VERSION "created by canmatrix"

NS_ :

BS_:

BU_: ETAS SRRL SRRR FRR IBC EPS

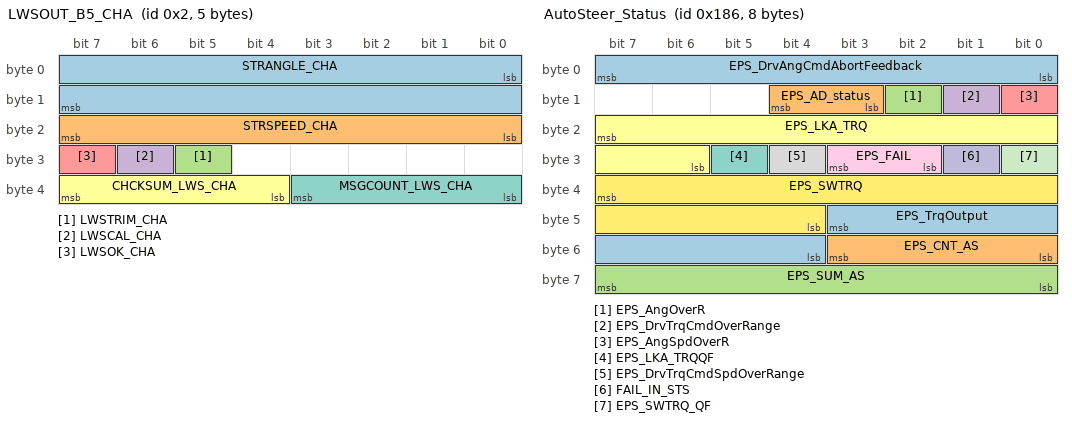
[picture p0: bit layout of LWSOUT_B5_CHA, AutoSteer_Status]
BO_ 2 LWSOUT_B5_CHA: 5 EPS
 SG_ STRANGLE_CHA : 0|16@1- (0.1,0) [-780|780] "deg"  ETAS,SRRL,SRRR,FRR
 SG_ STRSPEED_CHA : 16|8@1+ (4,0) [0|1016] "deg/s"  ETAS,SRRL,SRRR,FRR
 SG_ LWSTRIM_CHA : 29|1@1+ (1,0) [0|1] ""  ETAS,SRRL,SRRR,FRR
 SG_ LWSCAL_CHA : 30|1@1+ (1,0) [0|1] ""  ETAS,SRRL,SRRR,FRR
 SG_ LWSOK_CHA : 31|1@1+ (1,0) [0|1] ""  ETAS,SRRL,SRRR,FRR
 SG_ CHCKSUM_LWS_CHA : 36|4@1+ (1,0) [0|15] ""  ETAS,SRRL,SRRR,FRR
 SG_ MSGCOUNT_LWS_CHA : 32|4@1+ (1,0) [0|15] ""  ETAS,SRRL,SRRR,FRR

BO_ 390 AutoSteer_Status: 8 EPS
 SG_ EPS_DrvAngCmdAbortFeedback : 7|8@0+ (1,0) [0|128] ""  ETAS
 SG_ EPS_AD_status : 12|2@0+ (1,0) [0|3] ""  ETAS
 SG_ EPS_AngOverR : 10|1@0+ (1,0) [0|1] ""  ETAS
 SG_ EPS_DrvTrqCmdOverRange : 9|1@0+ (1,0) [0|1] ""  ETAS
 SG_ EPS_AngSpdOverR : 8|1@0+ (1,0) [0|1] ""  ETAS
 SG_ EPS_LKA_TRQ : 23|10@0- (0.01,0) [-5|5] "Nm"  ETAS
 SG_ EPS_LKA_TRQQF : 29|1@0+ (1,0) [0|1] ""  ETAS
 SG_ EPS_DrvTrqCmdSpdOverRange : 28|1@0+ (1,0) [0|1] ""  ETAS
 SG_ EPS_FAIL : 27|2@0+ (1,0) [0|3] ""  ETAS
 SG_ FAIL_IN_STS : 25|1@0+ (1,0) [0|1] ""  ETAS
 SG_ EPS_SWTRQ_QF : 24|1@0+ (1,0) [0|1] ""  ETAS
 SG_ EPS_SWTRQ : 39|12@0- (0.01,0) [-12|12] "Nm"  ETAS
 SG_ EPS_TrqOutput : 43|8@0- (0.1,0) [-12|12] "Nm"  ETAS
 SG_ EPS_CNT_AS : 51|4@0+ (1,0) [0|15] ""  ETAS
 SG_ EPS_SUM_AS : 63|8@0+ (1,0) [0|255] ""  ETAS

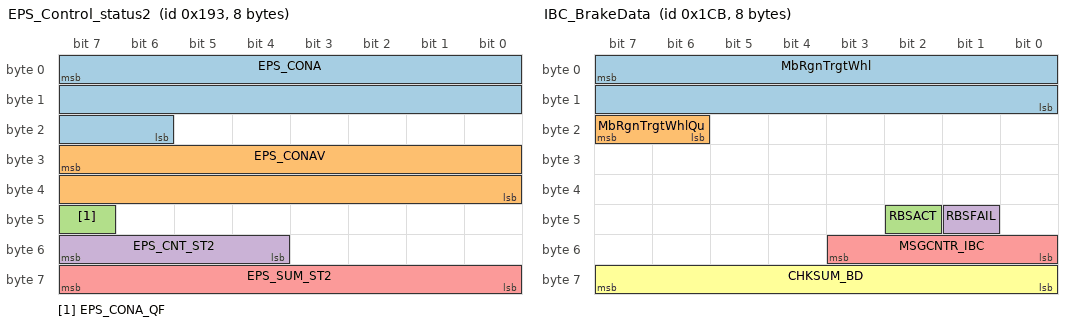
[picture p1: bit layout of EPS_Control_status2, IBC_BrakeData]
BO_ 403 EPS_Control_status2: 8 EPS
 SG_ EPS_CONA : 7|18@0- (0.01,0) [-780|780] "deg"  ETAS
 SG_ EPS_CONAV : 31|16@0+ (0.1,-1000) [-1000|1000] "deg/s"  ETAS
 SG_ EPS_CONA_QF : 47|1@0+ (1,0) [0|1] ""  ETAS
 SG_ EPS_CNT_ST2 : 55|4@0+ (1,0) [0|15] ""  ETAS
 SG_ EPS_SUM_ST2 : 63|8@0+ (1,0) [0|255] ""  ETAS

BO_ 682 BrakeSystemtoADAS_MSG1_CHA: 8 IBC
 SG_ ADAS_PTC_STATUS_CHA : 11|2@0+ (1,0) [0|3] ""  ETAS
 SG_ SIGNAL_SOURCING_CHA : 9|2@0+ (1,0) [0|3] ""  ETAS
 SG_ AEB_ENBL_CHA : 23|1@0+ (1,0) [0|1] ""  ETAS
 SG_ AEB_STATUS_CHA : 22|1@0+ (1,0) [0|1] ""  ETAS,SRRL,SRRR,FRR
 SG_ AEB_ALIVE_CHA : 21|1@0+ (1,0) [0|1] ""  ETAS
 SG_ PREFILL_ENBL_CHA : 20|1@0+ (1,0) [0|1] ""  ETAS
 SG_ PREFILL_STATUS_CHA : 19|1@0+ (1,0) [0|1] ""  ETAS
 SG_ PREFILL_ALIVE_CHA : 18|1@0+ (1,0) [0|1] ""  ETAS
 SG_ ABA_ENBL_CHA : 17|1@0+ (1,0) [0|1] ""  ETAS
 SG_ ABA_STATUS_CHA : 16|1@0+ (1,0) [0|1] ""  ETAS
 SG_ ABA_ALIVE_CHA : 31|1@0+ (1,0) [0|1] ""  ETAS
 SG_ AWB_ENBL_CHA : 30|1@0+ (1,0) [0|1] ""  ETAS
 SG_ AWB_STATUS_CHA : 29|1@0+ (1,0) [0|1] ""  ETAS
 SG_ AWB_ALIVE_CHA : 28|1@0+ (1,0) [0|1] ""  ETAS
 SG_ ACC_CDD_ENBL_CHA : 27|1@0+ (1,0) [0|1] ""  ETAS
 SG_ ACC_CDD_STATUS_CHA : 26|1@0+ (1,0) [0|1] ""  ETAS
 SG_ ACC_CDD_ALIVE_CHA : 25|1@0+ (1,0) [0|1] ""  ETAS
 SG_ ACC_CDD_TEMP_CHA : 36|1@0+ (1,0) [0|1] ""  ETAS
 SG_ WCBF_EXIST_CHA : 54|1@0+ (1,0) [0|1] ""  ETAS
 SG_ VEH_STD_STILL_CHA : 53|2@0+ (1,0) [0|3] ""  ETAS,SRRL,SRRR,FRR
 SG_ MSG_CNT_BAM_CHA : 51|4@0+ (1,0) [0|15] ""  ETAS,SRRL,SRRR,FRR
 SG_ CHKSUM_BAM_CHA : 63|8@0+ (1,0) [0|255] ""  ETAS,SRRL,SRRR,FRR

BO_ 459 IBC_BrakeData: 8 IBC
 SG_ MbRgnTrgtWhl : 7|16@0+ (1,0) [0|32768] "Nm"  ETAS
 SG_ MbRgnTrgtWhlQu : 23|2@0+ (1,0) [0|2] ""  ETAS
 SG_ RBSACT : 42|1@0+ (1,0) [0|1] ""  ETAS
 SG_ RBSFAIL : 41|1@0+ (1,0) [0|1] ""  ETAS
 SG_ MSGCNTR_IBC : 51|4@0+ (1,0) [0|15] ""  ETAS
 SG_ CHKSUM_BD : 63|8@0+ (1,0) [0|255] ""  ETAS

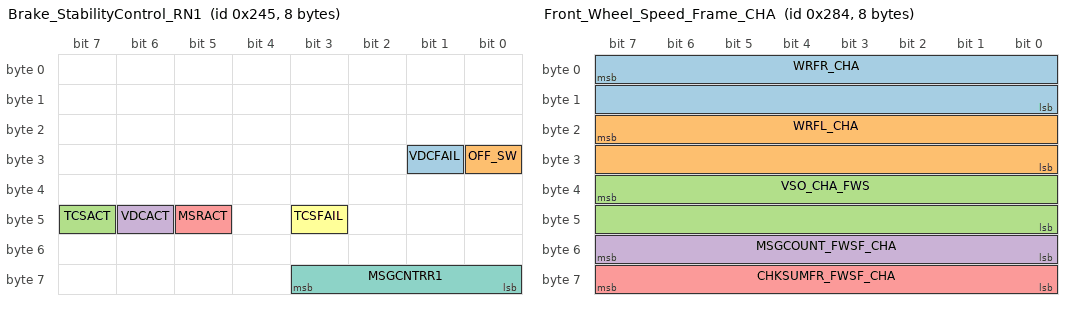
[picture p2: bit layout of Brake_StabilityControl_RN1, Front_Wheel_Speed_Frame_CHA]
BO_ 581 Brake_StabilityControl_RN1: 8 IBC
 SG_ VDCFAIL : 25|1@0+ (1,0) [0|1] ""  ETAS
 SG_ OFF_SW : 24|1@0+ (1,0) [0|1] ""  ETAS
 SG_ TCSACT : 47|1@0+ (1,0) [0|1] ""  ETAS
 SG_ VDCACT : 46|1@0+ (1,0) [0|1] ""  ETAS
 SG_ MSRACT : 45|1@0+ (1,0) [0|1] ""  ETAS
 SG_ TCSFAIL : 43|1@0+ (1,0) [0|1] ""  ETAS
 SG_ MSGCNTRR1 : 59|4@0+ (1,0) [0|15] ""  ETAS

BO_ 644 Front_Wheel_Speed_Frame_CHA: 8 IBC
 SG_ WRFR_CHA : 7|16@0+ (0.0416666666666667,0) [0|2730.58333333333] "rpm"  ETAS,SRRL,SRRR,FRR
 SG_ WRFL_CHA : 23|16@0+ (0.0416666666666667,0) [0|2730.58333333333] "rpm"  ETAS,SRRL,SRRR,FRR
 SG_ VSO_CHA_FWS : 39|16@0+ (0.01,0) [0|655.34] "km/h"  ETAS,SRRL,SRRR,FRR
 SG_ MSGCOUNT_FWSF_CHA : 55|8@0+ (1,0) [0|255] ""  ETAS,SRRL,SRRR,FRR
 SG_ CHKSUMFR_FWSF_CHA : 63|8@0+ (1,0) [0|255] ""  ETAS,SRRL,SRRR,FRR

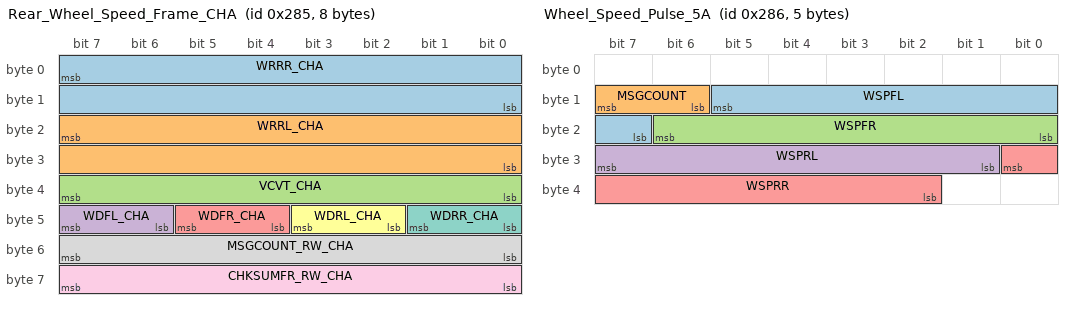
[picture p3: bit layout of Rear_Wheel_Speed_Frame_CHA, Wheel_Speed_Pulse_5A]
BO_ 645 Rear_Wheel_Speed_Frame_CHA: 8 IBC
 SG_ WRRR_CHA : 7|16@0+ (0.0416666666666667,0) [0|2730.58333333333] "rpm"  ETAS,SRRL,SRRR,FRR
 SG_ WRRL_CHA : 23|16@0+ (0.0416666666666667,0) [0|2730.58333333333] "rpm"  ETAS,SRRL,SRRR,FRR
 SG_ VCVT_CHA : 39|8@0+ (1,0) [0|255] "km/h"  ETAS,SRRL,SRRR,FRR
 SG_ WDFL_CHA : 47|2@0+ (1,0) [0|3] ""  ETAS,SRRL,SRRR,FRR
 SG_ WDFR_CHA : 45|2@0+ (1,0) [0|3] ""  ETAS,SRRL,SRRR,FRR
 SG_ WDRL_CHA : 43|2@0+ (1,0) [0|3] ""  ETAS,SRRL,SRRR,FRR
 SG_ WDRR_CHA : 41|2@0+ (1,0) [0|3] ""  ETAS,SRRL,SRRR,FRR
 SG_ MSGCOUNT_RW_CHA : 55|8@0+ (1,0) [0|255] ""  ETAS,SRRL,SRRR,FRR
 SG_ CHKSUMFR_RW_CHA : 63|8@0+ (1,0) [0|255] ""  ETAS,SRRL,SRRR,FRR

BO_ 646 Wheel_Speed_Pulse_5A: 5 IBC
 SG_ WSPFL : 13|7@0+ (1,0) [1|96] "top"  ETAS
 SG_ MSGCOUNT : 15|2@0+ (1,0) [0|3] ""  ETAS
 SG_ WSPFR : 22|7@0+ (1,0) [1|96] "top"  ETAS
 SG_ WSPRL : 31|7@0+ (1,0) [1|96] "top"  ETAS
 SG_ WSPRR : 24|7@0+ (1,0) [1|96] "top"  ETAS

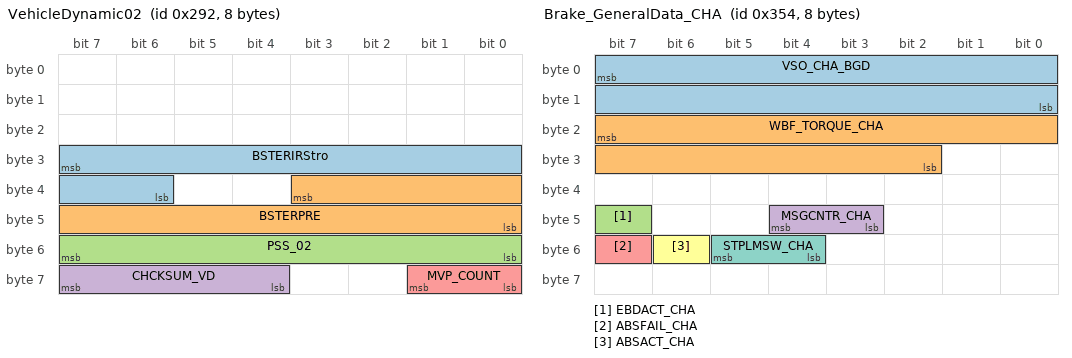
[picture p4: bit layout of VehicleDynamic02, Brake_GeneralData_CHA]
BO_ 658 VehicleDynamic02: 8 IBC
 SG_ BSTERIRStro : 31|10@0+ (0.05,-5) [-5|46.1] "mm"  ETAS
 SG_ BSTERPRE : 35|12@0+ (0.1,-5) [-5|302.1] "bar"  ETAS
 SG_ PSS_02 : 55|8@0+ (1,0) [0|254] "bar"  ETAS
 SG_ CHCKSUM_VD : 63|4@0+ (1,0) [0|15] ""  ETAS
 SG_ MVP_COUNT : 57|2@0+ (1,0) [0|3] ""  ETAS

BO_ 852 Brake_GeneralData_CHA: 8 IBC
 SG_ VSO_CHA_BGD : 7|16@0+ (0.01,0) [0|655.34] "km/h"  ETAS
 SG_ WBF_TORQUE_CHA : 23|14@0+ (2,0) [0|32764] "NM"  ETAS
 SG_ EBDACT_CHA : 47|1@0+ (1,0) [0|1] ""  ETAS,SRRL,SRRR,FRR
 SG_ MSGCNTR_CHA : 44|2@0+ (1,0) [0|3] ""  ETAS,SRRL,SRRR,FRR
 SG_ ABSFAIL_CHA : 55|1@0+ (1,0) [0|1] ""  ETAS,SRRL,SRRR,FRR
 SG_ ABSACT_CHA : 54|1@0+ (1,0) [0|1] ""  ETAS,SRRL,SRRR,FRR
 SG_ STPLMSW_CHA : 53|2@0+ (1,0) [0|3] ""  ETAS,SRRL,SRRR,FRR

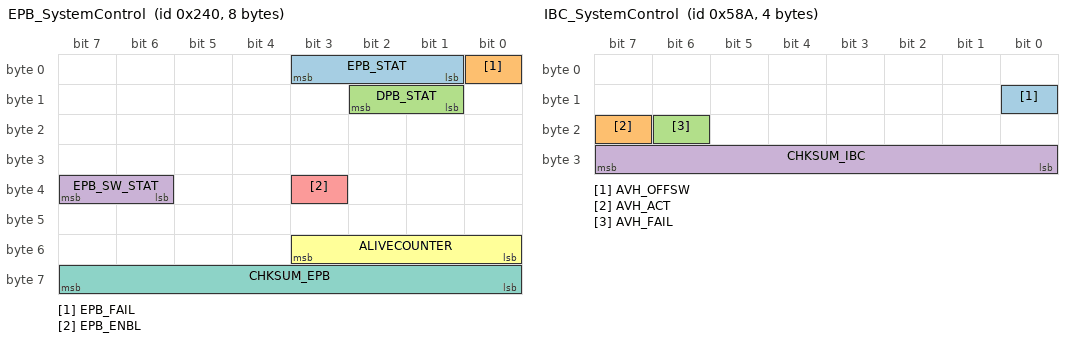
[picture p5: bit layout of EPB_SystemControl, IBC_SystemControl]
BO_ 576 EPB_SystemControl: 8 IBC
 SG_ EPB_STAT : 3|3@0+ (1,0) [0|7] ""  ETAS
 SG_ EPB_FAIL : 0|1@0+ (1,0) [0|1] ""  ETAS
 SG_ DPB_STAT : 10|2@0+ (1,0) [0|3] ""  ETAS
 SG_ EPB_SW_STAT : 39|2@0+ (1,0) [0|3] ""  ETAS
 SG_ EPB_ENBL : 35|1@0+ (1,0) [0|1] ""  ETAS
 SG_ ALIVECOUNTER : 51|4@0+ (1,0) [0|15] ""  ETAS
 SG_ CHKSUM_EPB : 63|8@0+ (1,0) [0|255] ""  ETAS

BO_ 1418 IBC_SystemControl: 4 IBC
 SG_ AVH_OFFSW : 8|1@0+ (1,0) [0|1] ""  ETAS
 SG_ AVH_ACT : 23|1@0+ (1,0) [0|1] ""  ETAS
 SG_ AVH_FAIL : 22|1@0+ (1,0) [0|1] ""  ETAS
 SG_ CHKSUM_IBC : 31|8@0+ (1,0) [0|255] ""  ETAS

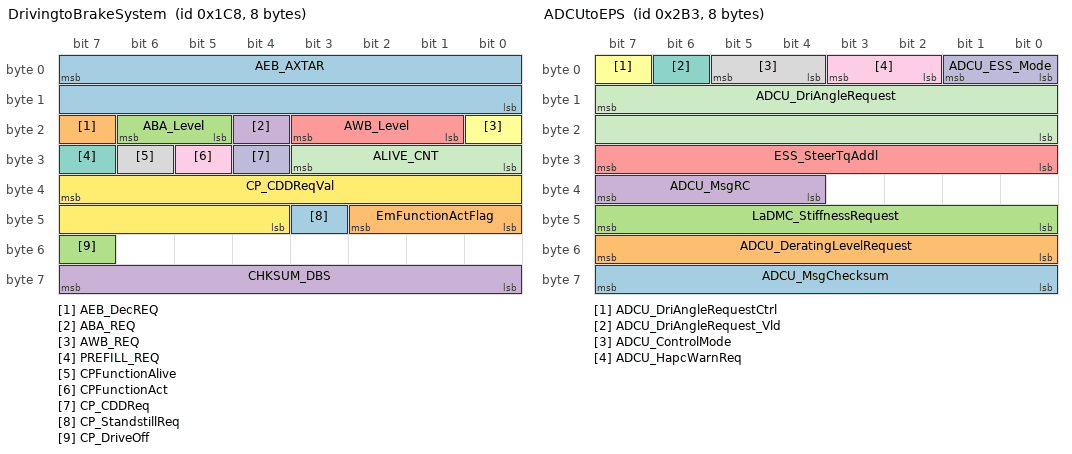
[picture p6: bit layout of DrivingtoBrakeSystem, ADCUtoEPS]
BO_ 456 DrivingtoBrakeSystem: 8 ETAS
 SG_ AEB_AXTAR : 7|16@0+ (0.0004882,-16) [-16|-0.0031506] "m/s2"  IBC
 SG_ AEB_DecREQ : 23|1@0+ (1,0) [0|1] ""  IBC
 SG_ ABA_Level : 22|2@0+ (1,0) [0|3] ""  IBC
 SG_ ABA_REQ : 20|1@0+ (1,0) [0|1] ""  IBC
 SG_ AWB_Level : 19|3@0+ (1,0) [0|7] ""  IBC
 SG_ AWB_REQ : 16|1@0+ (1,0) [0|1] ""  IBC
 SG_ PREFILL_REQ : 31|1@0+ (1,0) [0|1] ""  IBC
 SG_ CPFunctionAlive : 30|1@0+ (1,0) [0|1] ""  IBC
 SG_ CPFunctionAct : 29|1@0+ (1,0) [0|1] ""  IBC
 SG_ CP_CDDReq : 28|1@0+ (1,0) [0|1] ""  IBC
 SG_ ALIVE_CNT : 27|4@0+ (1,0) [0|15] ""  IBC
 SG_ CP_CDDReqVal : 39|12@0+ (5,0) [0|20470] "Nm"  IBC
 SG_ CP_StandstillReq : 43|1@0+ (1,0) [0|1] ""  IBC
 SG_ EmFunctionActFlag : 42|3@0+ (1,0) [0|7] ""  IBC
 SG_ CP_DriveOff : 55|1@0+ (1,0) [0|1] ""  IBC
 SG_ CHKSUM_DBS : 63|8@0+ (1,0) [0|255] ""  IBC

BO_ 691 ADCUtoEPS: 8 ETAS
 SG_ ADCU_MsgChecksum : 63|8@0+ (1,0) [0|255] "" Vector__XXX
 SG_ ADCU_DeratingLevelRequest : 55|8@0+ (1,0) [0|100] "" Vector__XXX
 SG_ LaDMC_StiffnessRequest : 47|8@0+ (1,0) [0|100] "" Vector__XXX
 SG_ ADCU_MsgRC : 39|4@0+ (1,0) [0|15] "" Vector__XXX
 SG_ ESS_SteerTqAddl : 31|8@0- (0.1,0) [-12|12] "" Vector__XXX
 SG_ ADCU_DriAngleRequestCtrl : 7|1@0+ (1,0) [0|1] ""  EPS
 SG_ ADCU_DriAngleRequest_Vld : 6|1@0+ (1,0) [0|1] ""  EPS
 SG_ ADCU_ControlMode : 5|2@0+ (1,0) [0|3] ""  EPS
 SG_ ADCU_HapcWarnReq : 3|2@0+ (1,0) [0|3] ""  EPS
 SG_ ADCU_ESS_Mode : 1|2@0+ (1,0) [0|3] ""  EPS
 SG_ ADCU_DriAngleRequest : 15|16@0- (0.1,0) [-780|780] "degree"  EPS

CM_ SG_ 2 STRANGLE_CHA "Intel格式，整车其他ECU用到的方向盘转角信号，TAS传感器得到";
CM_ SG_ 2 STRSPEED_CHA "TAS传感器得到的方向盘转角速度信号,ACC";
CM_ SG_ 2 LWSTRIM_CHA "002信号初始化标志位";
CM_ SG_ 2 LWSCAL_CHA "002信号标定标志位";
CM_ SG_ 2 LWSOK_CHA "002方向盘转角信号fail信号,ACC";
CM_ SG_ 2 CHCKSUM_LWS_CHA "None";
CM_ SG_ 2 MSGCOUNT_LWS_CHA "None";
CM_ SG_ 390 EPS_DrvAngCmdAbortFeedback "表示横向控制器当前状态跳出 Active的原因
0x0:No error(正常工作)
0x1:Vehicle speed Invalid(行车：车速超
限大于 155kph；泊车：车速超限大于25kph)
0x2:Driver Interference（驾驶员干预触发）
0x3:ADCU Ctrl Request Invalid（包含checksum RC timeout等通信异常）
0x6:Request Angle Slope over range
0x7:Request Angle Value over range
0x8:Steering permanently error
Other:Reserved";
CM_ SG_ 390 EPS_AD_status "EPS发送与AD哪类功能握手的信号";
CM_ SG_ 390 EPS_AngOverR "EPS反馈请求的目标角度超限标志";
CM_ SG_ 390 EPS_DrvTrqCmdOverRange "EPS反馈请求的目标扭矩超限标志";
CM_ SG_ 390 EPS_AngSpdOverR "EPS反馈请求的目标角度梯度超限标志";
CM_ SG_ 390 EPS_LKA_TRQ "-";
CM_ SG_ 390 EPS_LKA_TRQQF "-";
CM_ SG_ 390 EPS_DrvTrqCmdSpdOverRange "EPS反馈请求的目标扭矩梯度超限标志";
CM_ SG_ 390 EPS_FAIL "当前转向系统控制器角度/扭矩控制功能的状态
0x0:Temporary inhibit
(转向系统转向控制功能处于临时抑
制状态，当前点火周期临时抑制条
件解除后，转向控制功能可激活);
0x1:Available for control
(转向系统转向控制功能可用但未激
活);
0x2:Active
(转向系统转向控制功能激活);
0x3:Permanently failed
(转向系统检测到相关严重故障角度/扭矩
控制功能被禁止使用，且在当前点
火循环不可恢复使用)";
CM_ SG_ 390 FAIL_IN_STS "EPS反馈的故障状态";
CM_ SG_ 390 EPS_SWTRQ_QF "EPS 反馈的驾驶员手力矩是否有效";
CM_ SG_ 390 EPS_SWTRQ "左正右负，EPS 反馈的驾驶员手力矩";
CM_ SG_ 390 EPS_TrqOutput "左正右负，EPS执行的总力矩";
CM_ SG_ 390 EPS_CNT_AS "-";
CM_ SG_ 390 EPS_SUM_AS "算法：
参考25953 NDS42中规定";
CM_ SG_ 403 EPS_CONA "左负右正，方向盘实际转角大小，电机位置传感器计算得到";
CM_ SG_ 403 EPS_CONAV "左负右正，方向盘实际转角速度";
CM_ SG_ 403 EPS_CONA_QF "方向盘实际转角大小有效位";
CM_ SG_ 403 EPS_CNT_ST2 "-";
CM_ SG_ 403 EPS_SUM_ST2 "算法：
参考25953 NDS42中规定";
CM_ SG_ 682 ADAS_PTC_STATUS_CHA "参与握手";
CM_ SG_ 682 SIGNAL_SOURCING_CHA "FO需求，新增，不参与握手";
CM_ SG_ 682 AEB_ENBL_CHA "-";
CM_ SG_ 682 AEB_STATUS_CHA "-";
CM_ SG_ 682 AEB_ALIVE_CHA "-";
CM_ SG_ 682 PREFILL_ENBL_CHA "-";
CM_ SG_ 682 PREFILL_STATUS_CHA "-";
CM_ SG_ 682 PREFILL_ALIVE_CHA "-";
CM_ SG_ 682 ABA_ENBL_CHA "-";
CM_ SG_ 682 ABA_STATUS_CHA "-";
CM_ SG_ 682 ABA_ALIVE_CHA "-";
CM_ SG_ 682 AWB_ENBL_CHA "-";
CM_ SG_ 682 AWB_STATUS_CHA "-";
CM_ SG_ 682 AWB_ALIVE_CHA "-";
CM_ SG_ 682 ACC_CDD_ENBL_CHA "ACC";
CM_ SG_ 682 ACC_CDD_STATUS_CHA "ACC";
CM_ SG_ 682 ACC_CDD_ALIVE_CHA "ACC";
CM_ SG_ 682 ACC_CDD_TEMP_CHA "-";
CM_ SG_ 682 WCBF_EXIST_CHA "ACC";
CM_ SG_ 682 VEH_STD_STILL_CHA "ACC";
CM_ SG_ 682 MSG_CNT_BAM_CHA "-";
CM_ SG_ 682 CHKSUM_BAM_CHA "-";
CM_ SG_ 459 MbRgnTrgtWhl "CRBS请求电机回收扭矩（轮端）";
CM_ SG_ 459 MbRgnTrgtWhlQu "CRBS请求电机回收扭矩有效标志位";
CM_ SG_ 459 RBSACT "CRBS功能作动标志位";
CM_ SG_ 459 RBSFAIL "CRBS功能故障标志位";
CM_ SG_ 459 MSGCNTR_IBC "ACC";
CM_ SG_ 459 CHKSUM_BD "ACC";
CM_ SG_ 581 VDCFAIL "ESP功能故障标志位，ACC";
CM_ SG_ 581 OFF_SW "ESP功能关闭标志位, ACC";
CM_ SG_ 581 TCSACT "TCS降扭作动标志位,ACC";
CM_ SG_ 581 VDCACT "ESP功能作动标志位,ACC";
CM_ SG_ 581 MSRACT "TCS升扭作动标志位";
CM_ SG_ 581 TCSFAIL "TCS功能故障标志位,ACC";
CM_ SG_ 581 MSGCNTRR1 "‘-， ACC";
CM_ SG_ 644 WRFR_CHA "右前轮轮速信号,ACC";
CM_ SG_ 644 WRFL_CHA "左前轮轮速信号,ACC";
CM_ SG_ 644 VSO_CHA_FWS "车速信号,ACC";
CM_ SG_ 644 MSGCOUNT_FWSF_CHA "ACC";
CM_ SG_ 644 CHKSUMFR_FWSF_CHA "ACC";
CM_ SG_ 645 WRRR_CHA "右后轮轮速信号,ACC";
CM_ SG_ 645 WRRL_CHA "左后轮轮速信号,ACC";
CM_ SG_ 645 VCVT_CHA "滑移时估计的车辆速度
FO需求新增，预留";
CM_ SG_ 645 WDFL_CHA "左前轮方向信号,ACC";
CM_ SG_ 645 WDFR_CHA "右前轮方向信号,ACC";
CM_ SG_ 645 WDRL_CHA "左后轮方向信号,ACC";
CM_ SG_ 645 WDRR_CHA "右后轮方向信号,ACC";
CM_ SG_ 645 MSGCOUNT_RW_CHA "ACC";
CM_ SG_ 645 CHKSUMFR_RW_CHA "ACC";
CM_ SG_ 646 WSPFL "左前轮脉冲信号";
CM_ SG_ 646 MSGCOUNT "None";
CM_ SG_ 646 WSPFR "右前轮脉冲信号";
CM_ SG_ 646 WSPRL "左后轮脉冲信号";
CM_ SG_ 646 WSPRR "右后轮脉冲信号";
CM_ SG_ 658 BSTERIRStro "制动踏板行程信号";
CM_ SG_ 658 BSTERPRE "轮端制动压力,ACC";
CM_ SG_ 658 PSS_02 "IBC机械主缸制动压力信号,ACC";
CM_ SG_ 658 CHCKSUM_VD "-";
CM_ SG_ 658 MVP_COUNT "-";
CM_ SG_ 852 VSO_CHA_BGD "车速信号（同284，仅周期不同）";
CM_ SG_ 852 WBF_TORQUE_CHA "轮边液压制动力矩（不包含CRBS的回收负扭）";
CM_ SG_ 852 EBDACT_CHA "EBD功能作动标志位";
CM_ SG_ 852 MSGCNTR_CHA "-";
CM_ SG_ 852 ABSFAIL_CHA "ABS功能故障标志位,ACC";
CM_ SG_ 852 ABSACT_CHA "ABS功能作动标志位,ACC";
CM_ SG_ 852 STPLMSW_CHA "制动踏板是否踩下标志位，ACC";
CM_ SG_ 576 EPB_STAT "EPKB当前状态,ACC";
CM_ SG_ 576 EPB_FAIL "EPKB是否故障标志位";
CM_ SG_ 576 DPB_STAT "DPB功能作动标志位,ACC";
CM_ SG_ 576 EPB_SW_STAT "EPKB开关状态（P档开关联动，无释放状态）";
CM_ SG_ 576 EPB_ENBL "EPKB当前是否可响应外部请求标志位";
CM_ SG_ 576 ALIVECOUNTER "-";
CM_ SG_ 576 CHKSUM_EPB "-";
CM_ SG_ 1418 AVH_OFFSW "AVH开关是否开启";
CM_ SG_ 1418 AVH_ACT "AVH功能作动标志位,ACC";
CM_ SG_ 1418 AVH_FAIL "AVH功能故障标志位";
CM_ SG_ 1418 CHKSUM_IBC "-";
CM_ SG_ 456 AEB_AXTAR "FEB减速度接口";
CM_ SG_ 456 AEB_DecREQ "FEB减速度请求标志位";
CM_ SG_ 456 ABA_Level "ABA功能Level 请求";
CM_ SG_ 456 ABA_REQ "ABA功能请求标志位";
CM_ SG_ 456 AWB_Level "AWB功能Level 请求";
CM_ SG_ 456 AWB_REQ "AWB功能请求标志位";
CM_ SG_ 456 PREFILL_REQ "预填充请求";
CM_ SG_ 456 CPFunctionAlive "ICC(ACC/NOA)功能故障标志位";
CM_ SG_ 456 CPFunctionAct "ICC(ACC/NOA)功能作动标志位";
CM_ SG_ 456 CP_CDDReq "ACC/NOA减速扭矩请求标志位";
CM_ SG_ 456 ALIVE_CNT "-";
CM_ SG_ 456 CP_CDDReqVal "ACC/NOA减速扭矩请求值";
CM_ SG_ 456 CP_StandstillReq "ACC/NOA停车请求标志位";
CM_ SG_ 456 EmFunctionActFlag "ADCU Ax控制口功能激活情况";
CM_ SG_ 456 CP_DriveOff "ACC/NOA起步请求标志位";
CM_ SG_ 456 CHKSUM_DBS "-";
CM_ SG_ 691 ESS_SteerTqAddl "左正右负，ESS请求的叠加扭矩（实际请求不超过5Nm）";
CM_ SG_ 691 ADCU_DriAngleRequestCtrl "ADCU 是否请求转角/扭矩控制";
CM_ SG_ 691 ADCU_DriAngleRequest_Vld "ADCU 转角/扭矩请求值有效位";
CM_ SG_ 691 ADCU_ControlMode "新增，ADCU请求所属功能激活标志位";
CM_ SG_ 691 ADCU_HapcWarnReq "预留，震动提醒";
CM_ SG_ 691 ADCU_ESS_Mode "ESS紧急转向功能设立单独信号";
CM_ SG_ 691 ADCU_DriAngleRequest "ADCU 转角请求值，表示请求转向系统执行目标转向角度控制的值，其代表直接方向盘转角目标值（非单独叠加角度值）,左负右正";
BA_DEF_ BO_  "DiagConnection" STRING ;
BA_DEF_ BO_  "GenMsgCycleTime" INT 0 65535;
BA_DEF_ BO_  "GenMsgILSupport" ENUM  "Yes","No";
BA_DEF_ BO_  "GenMsgSendType" ENUM  "NoSigSendType","Cyclic","Event";
BA_DEF_ BO_  "GenSigSendType" ENUM  "Cyclic","OnWrite","OnWriteWithRepetition","OnChange","OnChangeWithRepetition","IfActive","IfActiveWithRepeition","NoSigSendType";
BA_DEF_ BO_  "VFrameFormat" ENUM  "StandardCAN","ExtendedCAN","reserved","reserved","reserved","reserved","reserved","reserved","reserved","reserved","reserved","reserved","reserved","reserved","StandardCAN_FD","ExtendedCAN_FD";
BA_DEF_  "BusType" STRING ;
BA_DEF_ BO_  "CANFD_BRS" ENUM  "0","1";
BA_DEF_DEF_  "DiagConnection" "0x0";
BA_DEF_DEF_  "GenMsgCycleTime" 0;
BA_DEF_DEF_  "GenMsgILSupport" "Yes";
BA_DEF_DEF_  "GenMsgSendType" "NoSigSendType";
BA_DEF_DEF_  "GenSigSendType" "NoSigSendType";
BA_DEF_DEF_  "VFrameFormat" "";
BA_DEF_DEF_  "BusType" "CAN";
BA_DEF_DEF_  "CANFD_BRS" "1";
BA_ "BusType" "CAN FD";
BA_ "GenSigSendType" BO_ 2 0;
BA_ "GenMsgSendType" BO_ 2 1;
BA_ "GenMsgCycleTime" BO_ 2 10;
BA_ "VFrameFormat" BO_ 2 14;
BA_ "GenSigSendType" BO_ 390 0;
BA_ "GenMsgSendType" BO_ 390 1;
BA_ "GenMsgCycleTime" BO_ 390 10;
BA_ "VFrameFormat" BO_ 390 14;
BA_ "GenSigSendType" BO_ 403 0;
BA_ "GenMsgSendType" BO_ 403 1;
BA_ "GenMsgCycleTime" BO_ 403 10;
BA_ "VFrameFormat" BO_ 403 14;
BA_ "GenSigSendType" BO_ 682 0;
BA_ "GenMsgSendType" BO_ 682 1;
BA_ "GenMsgCycleTime" BO_ 682 20;
BA_ "VFrameFormat" BO_ 682 14;
BA_ "GenSigSendType" BO_ 459 0;
BA_ "GenMsgSendType" BO_ 459 1;
BA_ "GenMsgCycleTime" BO_ 459 10;
BA_ "VFrameFormat" BO_ 459 14;
BA_ "GenSigSendType" BO_ 581 0;
BA_ "GenMsgSendType" BO_ 581 1;
BA_ "GenMsgCycleTime" BO_ 581 20;
BA_ "VFrameFormat" BO_ 581 14;
BA_ "GenSigSendType" BO_ 644 0;
BA_ "GenMsgSendType" BO_ 644 1;
BA_ "GenMsgCycleTime" BO_ 644 20;
BA_ "VFrameFormat" BO_ 644 14;
BA_ "GenSigSendType" BO_ 645 0;
BA_ "GenMsgSendType" BO_ 645 1;
BA_ "GenMsgCycleTime" BO_ 645 20;
BA_ "VFrameFormat" BO_ 645 14;
BA_ "GenSigSendType" BO_ 646 0;
BA_ "GenMsgSendType" BO_ 646 1;
BA_ "GenMsgCycleTime" BO_ 646 20;
BA_ "VFrameFormat" BO_ 646 14;
BA_ "GenSigSendType" BO_ 658 0;
BA_ "GenMsgSendType" BO_ 658 1;
BA_ "GenMsgCycleTime" BO_ 658 20;
BA_ "VFrameFormat" BO_ 658 14;
BA_ "GenSigSendType" BO_ 852 0;
BA_ "GenMsgSendType" BO_ 852 1;
BA_ "GenMsgCycleTime" BO_ 852 40;
BA_ "VFrameFormat" BO_ 852 14;
BA_ "GenSigSendType" BO_ 576 0;
BA_ "GenMsgSendType" BO_ 576 1;
BA_ "GenMsgCycleTime" BO_ 576 20;
BA_ "VFrameFormat" BO_ 576 14;
BA_ "GenSigSendType" BO_ 1418 0;
BA_ "GenMsgSendType" BO_ 1418 1;
BA_ "GenMsgCycleTime" BO_ 1418 20;
BA_ "VFrameFormat" BO_ 1418 14;
BA_ "GenSigSendType" BO_ 456 0;
BA_ "GenMsgSendType" BO_ 456 1;
BA_ "GenMsgCycleTime" BO_ 456 20;
BA_ "VFrameFormat" BO_ 456 14;
BA_ "GenSigSendType" BO_ 691 0;
BA_ "GenMsgSendType" BO_ 691 1;
BA_ "GenMsgCycleTime" BO_ 691 20;
BA_ "VFrameFormat" BO_ 691 14;
VAL_ 2 LWSTRIM_CHA 0 "0:Unfinish" 1 "1:Finish" ;
VAL_ 2 LWSCAL_CHA 0 "0:Unfinish" 1 "1:Finish" ;
VAL_ 2 LWSOK_CHA 0 "0:Abnormal" 1 "1:Normal" ;
VAL_ 390 EPS_DrvAngCmdAbortFeedback 0 "0:No error(正常工作)" 1 "1:Driver Interference（驾驶员干预触发）" 2 "2:Vehicle speed Invalid(车速超限大于155kph)" 3 "3:Abnormal CAN Input (ADAS相关CAN信号无效）" 4 "4:Request Angle Slope over range" 5 "5:Request Angle Value over range" 6 "6:Internal Fault (EPS出现内部可恢复故障）" 7 "7:EPS Failure (EPS严重故障）" 8 "8:Request Torque Slope over range（仅ESS扭矩接口）" 9 "9:Request Torque Value over range（仅ESS扭矩接口）" 10 "A~F:Reserved" 11 "A~F:Reserved" 12 "A~F:Reserved" 13 "A~F:Reserved" 14 "A~F:Reserved" ;
VAL_ 390 EPS_AD_status 0 "0:Inactive" 1 "1:LKA active" 2 "2:APA active" 3 "3:ESS active" ;
VAL_ 390 EPS_AngOverR 0 "0b:Not over range" 1 "1b:Over range" ;
VAL_ 390 EPS_DrvTrqCmdOverRange 0 "0:Not over range" 1 "1:Over range" ;
VAL_ 390 EPS_AngSpdOverR 0 "0b:Not over range" 1 "1b:Over range" ;
VAL_ 390 EPS_LKA_TRQ 0 ":" 1 ":" 2 ":" 3 ":" 4 ":" 5 ":" 6 ":" 7 ":" 8 ":" 9 ":" 10 ":" 11 ":" 12 ":" 13 ":" 14 ":" 15 ":" 16 ":" 17 ":" 18 ":" 19 ":" 20 ":" 21 ":" 22 ":" 23 ":" 24 ":" 25 ":" 26 ":" 27 ":" 28 ":" 29 ":" 30 ":" 31 ":" 32 ":" 33 ":" 34 ":" 35 ":" 36 ":" 37 ":" 38 ":" 39 ":" 40 ":" 41 ":" 42 ":" 43 ":" 44 ":" 45 ":" 46 ":" 47 ":" 48 ":" 49 ":" 50 ":" 51 ":" 52 ":" 53 ":" 54 ":" 55 ":" 56 ":" 57 ":" 58 ":" 59 ":" 60 ":" 61 ":" 62 ":" 63 ":" 64 ":" 65 ":" 66 ":" 67 ":" 68 ":" 69 ":" 70 ":" 71 ":" 72 ":" 73 ":" 74 ":" 75 ":" 76 ":" 77 ":" 78 ":" 79 ":" 80 ":" 81 ":" 82 ":" 83 ":" 84 ":" 85 ":" 86 ":" 87 ":" 88 ":" 89 ":" 90 ":" 91 ":" 92 ":" 93 ":" 94 ":" 95 ":" 96 ":" 97 ":" 98 ":" 99 ":" 100 ":" 101 ":" 102 ":" 103 ":" 104 ":" 105 ":" 106 ":" 107 ":" 108 ":" 109 ":" 110 ":" 111 ":" 112 ":" 113 ":" 114 ":" 115 ":" 116 ":" 117 ":" 118 ":" 119 ":" 120 ":" 121 ":" 122 ":" 123 ":" 124 ":" 125 ":" 126 ":" 127 ":" 128 ":" 129 ":" 130 ":" 131 ":" 132 ":" 133 ":" 134 ":" 135 ":" 136 ":" 137 ":" 138 ":" 139 ":" 140 ":" 141 ":" 142 ":" 143 ":" 144 ":" 145 ":" 146 ":" 147 ":" 148 ":" 149 ":" 150 ":" 151 ":" 152 ":" 153 ":" 154 ":" 155 ":" 156 ":" 157 ":" 158 ":" 159 ":" 160 ":" 161 ":" 162 ":" 163 ":" 164 ":" 165 ":" 166 ":" 167 ":" 168 ":" 169 ":" 170 ":" 171 ":" 172 ":" 173 ":" 174 ":" 175 ":" 176 ":" 177 ":" 178 ":" 179 ":" 180 ":" 181 ":" 182 ":" 183 ":" 184 ":" 185 ":" 186 ":" 187 ":" 188 ":" 189 ":" 190 ":" 191 ":" 192 ":" 193 ":" 194 ":" 195 ":" 196 ":" 197 ":" 198 ":" 199 ":" 200 ":" 201 ":" 202 ":" 203 ":" 204 ":" 205 ":" 206 ":" 207 ":" 208 ":" 209 ":" 210 ":" 211 ":" 212 ":" 213 ":" 214 ":" 215 ":" 216 ":" 217 ":" 218 ":" 219 ":" 220 ":" 221 ":" 222 ":" 223 ":" 224 ":" 225 ":" 226 ":" 227 ":" 228 ":" 229 ":" 230 ":" 231 ":" 232 ":" 233 ":" 234 ":" 235 ":" 236 ":" 237 ":" 238 ":" 239 ":" 240 ":" 241 ":" 242 ":" 243 ":" 244 ":" 245 ":" 246 ":" 247 ":" 248 ":" 249 ":" 250 ":" 251 ":" 252 ":" 253 ":" 254 ":" 255 ":" ;
VAL_ 390 EPS_LKA_TRQQF 0 "0b:Signal not available" 1 "1b:Signal available" ;
VAL_ 390 EPS_DrvTrqCmdSpdOverRange 0 "0b:Not over range" 1 "1b:Over range" ;
VAL_ 390 EPS_FAIL 0 "0:Temporary inhibit" 1 "1:Available for control" 2 "2:Active" 3 "3:Permanently failed" ;
VAL_ 390 FAIL_IN_STS 0 "0b:Normal" 1 "1b:Abnormal" ;
VAL_ 390 EPS_SWTRQ_QF 0 "0b:SteerWhlTrq signal available" 1 "1b:SteerWhlTrq signal not available" ;
VAL_ 390 EPS_SWTRQ 0 ":" 1 ":" 2 ":" 3 ":" 4 ":" 5 ":" 6 ":" 7 ":" 8 ":" 9 ":" 10 ":" 11 ":" 12 ":" 13 ":" 14 ":" 15 ":" 16 ":" 17 ":" 18 ":" 19 ":" 20 ":" 21 ":" 22 ":" 23 ":" 24 ":" 25 ":" 26 ":" 27 ":" 28 ":" 29 ":" 30 ":" 31 ":" 32 ":" 33 ":" 34 ":" 35 ":" 36 ":" 37 ":" 38 ":" 39 ":" 40 ":" 41 ":" 42 ":" 43 ":" 44 ":" 45 ":" 46 ":" 47 ":" 48 ":" 49 ":" 50 ":" 51 ":" 52 ":" 53 ":" 54 ":" 55 ":" 56 ":" 57 ":" 58 ":" 59 ":" 60 ":" 61 ":" 62 ":" 63 ":" 64 ":" 65 ":" 66 ":" 67 ":" 68 ":" 69 ":" 70 ":" 71 ":" 72 ":" 73 ":" 74 ":" 75 ":" 76 ":" 77 ":" 78 ":" 79 ":" 80 ":" 81 ":" 82 ":" 83 ":" 84 ":" 85 ":" 86 ":" 87 ":" 88 ":" 89 ":" 90 ":" 91 ":" 92 ":" 93 ":" 94 ":" 95 ":" 96 ":" 97 ":" 98 ":" 99 ":" 100 ":" 101 ":" 102 ":" 103 ":" 104 ":" 105 ":" 106 ":" 107 ":" 108 ":" 109 ":" 110 ":" 111 ":" 112 ":" 113 ":" 114 ":" 115 ":" 116 ":" 117 ":" 118 ":" 119 ":" 120 ":" 121 ":" 122 ":" 123 ":" 124 ":" 125 ":" 126 ":" 127 ":" 128 ":" 129 ":" 130 ":" 131 ":" 132 ":" 133 ":" 134 ":" 135 ":" 136 ":" 137 ":" 138 ":" 139 ":" 140 ":" 141 ":" 142 ":" 143 ":" 144 ":" 145 ":" 146 ":" 147 ":" 148 ":" 149 ":" 150 ":" 151 ":" 152 ":" 153 ":" 154 ":" 155 ":" 156 ":" 157 ":" 158 ":" 159 ":" 160 ":" 161 ":" 162 ":" 163 ":" 164 ":" 165 ":" 166 ":" 167 ":" 168 ":" 169 ":" 170 ":" 171 ":" 172 ":" 173 ":" 174 ":" 175 ":" 176 ":" 177 ":" 178 ":" 179 ":" 180 ":" 181 ":" 182 ":" 183 ":" 184 ":" 185 ":" 186 ":" 187 ":" 188 ":" 189 ":" 190 ":" 191 ":" 192 ":" 193 ":" 194 ":" 195 ":" 196 ":" 197 ":" 198 ":" 199 ":" 200 ":" 201 ":" 202 ":" 203 ":" 204 ":" 205 ":" 206 ":" 207 ":" 208 ":" 209 ":" 210 ":" 211 ":" 212 ":" 213 ":" 214 ":" 215 ":" 216 ":" 217 ":" 218 ":" 219 ":" 220 ":" 221 ":" 222 ":" 223 ":" 224 ":" 225 ":" 226 ":" 227 ":" 228 ":" 229 ":" 230 ":" 231 ":" 232 ":" 233 ":" 234 ":" 235 ":" 236 ":" 237 ":" 238 ":" 239 ":" 240 ":" 241 ":" 242 ":" 243 ":" 244 ":" 245 ":" 246 ":" 247 ":" 248 ":" 249 ":" 250 ":" 251 ":" 252 ":" 253 ":" 254 ":" 255 ":" ;
VAL_ 390 EPS_TrqOutput 0 ":" 1 ":" 2 ":" 3 ":" 4 ":" 5 ":" 6 ":" 7 ":" 8 ":" 9 ":" 10 ":" 11 ":" 12 ":" 13 ":" 14 ":" 15 ":" ;
VAL_ 390 EPS_CNT_AS 0 ":" 1 ":" 2 ":" 3 ":" 4 ":" 5 ":" 6 ":" 7 ":" 8 ":" 9 ":" 10 ":" 11 ":" 12 ":" 13 ":" 14 ":" 15 ":" ;
VAL_ 390 EPS_SUM_AS 0 ":" 1 ":" 2 ":" 3 ":" 4 ":" 5 ":" 6 ":" 7 ":" 8 ":" 9 ":" 10 ":" 11 ":" 12 ":" 13 ":" 14 ":" 15 ":" 16 ":" 17 ":" 18 ":" 19 ":" 20 ":" 21 ":" 22 ":" 23 ":" 24 ":" 25 ":" 26 ":" 27 ":" 28 ":" 29 ":" 30 ":" 31 ":" 32 ":" 33 ":" 34 ":" 35 ":" 36 ":" 37 ":" 38 ":" 39 ":" 40 ":" 41 ":" 42 ":" 43 ":" 44 ":" 45 ":" 46 ":" 47 ":" 48 ":" 49 ":" 50 ":" 51 ":" 52 ":" 53 ":" 54 ":" 55 ":" 56 ":" 57 ":" 58 ":" 59 ":" 60 ":" 61 ":" 62 ":" 63 ":" 64 ":" 65 ":" 66 ":" 67 ":" 68 ":" 69 ":" 70 ":" 71 ":" 72 ":" 73 ":" 74 ":" 75 ":" 76 ":" 77 ":" 78 ":" 79 ":" 80 ":" 81 ":" 82 ":" 83 ":" 84 ":" 85 ":" 86 ":" 87 ":" 88 ":" 89 ":" 90 ":" 91 ":" 92 ":" 93 ":" 94 ":" 95 ":" 96 ":" 97 ":" 98 ":" 99 ":" 100 ":" 101 ":" 102 ":" 103 ":" 104 ":" 105 ":" 106 ":" 107 ":" 108 ":" 109 ":" 110 ":" 111 ":" 112 ":" 113 ":" 114 ":" 115 ":" 116 ":" 117 ":" 118 ":" 119 ":" 120 ":" 121 ":" 122 ":" 123 ":" 124 ":" 125 ":" 126 ":" 127 ":" 128 ":" 129 ":" 130 ":" 131 ":" 132 ":" 133 ":" 134 ":" 135 ":" 136 ":" 137 ":" 138 ":" 139 ":" 140 ":" 141 ":" 142 ":" 143 ":" 144 ":" 145 ":" 146 ":" 147 ":" 148 ":" 149 ":" 150 ":" 151 ":" 152 ":" 153 ":" 154 ":" 155 ":" 156 ":" 157 ":" 158 ":" 159 ":" 160 ":" 161 ":" 162 ":" 163 ":" 164 ":" 165 ":" 166 ":" 167 ":" 168 ":" 169 ":" 170 ":" 171 ":" 172 ":" 173 ":" 174 ":" 175 ":" 176 ":" 177 ":" 178 ":" 179 ":" 180 ":" 181 ":" 182 ":" 183 ":" 184 ":" 185 ":" 186 ":" 187 ":" 188 ":" 189 ":" 190 ":" 191 ":" 192 ":" 193 ":" 194 ":" 195 ":" 196 ":" 197 ":" 198 ":" 199 ":" 200 ":" 201 ":" 202 ":" 203 ":" 204 ":" 205 ":" 206 ":" 207 ":" 208 ":" 209 ":" 210 ":" 211 ":" 212 ":" 213 ":" 214 ":" 215 ":" 216 ":" 217 ":" 218 ":" 219 ":" 220 ":" 221 ":" 222 ":" 223 ":" 224 ":" 225 ":" 226 ":" 227 ":" 228 ":" 229 ":" 230 ":" 231 ":" 232 ":" 233 ":" 234 ":" 235 ":" 236 ":" 237 ":" 238 ":" 239 ":" 240 ":" 241 ":" 242 ":" 243 ":" 244 ":" 245 ":" 246 ":" 247 ":" 248 ":" 249 ":" 250 ":" 251 ":" 252 ":" 253 ":" 254 ":" 255 ":" ;
VAL_ 403 EPS_CONAV 0 ":" 1 ":" 2 ":" 3 ":" 4 ":" 5 ":" 6 ":" 7 ":" 8 ":" 9 ":" 10 ":" 11 ":" 12 ":" 13 ":" 14 ":" 15 ":" 16 ":" 17 ":" 18 ":" 19 ":" 20 ":" 21 ":" 22 ":" 23 ":" 24 ":" 25 ":" 26 ":" 27 ":" 28 ":" 29 ":" 30 ":" 31 ":" 32 ":" 33 ":" 34 ":" 35 ":" 36 ":" 37 ":" 38 ":" 39 ":" 40 ":" 41 ":" 42 ":" 43 ":" 44 ":" 45 ":" 46 ":" 47 ":" 48 ":" 49 ":" 50 ":" 51 ":" 52 ":" 53 ":" 54 ":" 55 ":" 56 ":" 57 ":" 58 ":" 59 ":" 60 ":" 61 ":" 62 ":" 63 ":" 64 ":" 65 ":" 66 ":" 67 ":" 68 ":" 69 ":" 70 ":" 71 ":" 72 ":" 73 ":" 74 ":" 75 ":" 76 ":" 77 ":" 78 ":" 79 ":" 80 ":" 81 ":" 82 ":" 83 ":" 84 ":" 85 ":" 86 ":" 87 ":" 88 ":" 89 ":" 90 ":" 91 ":" 92 ":" 93 ":" 94 ":" 95 ":" 96 ":" 97 ":" 98 ":" 99 ":" 100 ":" 101 ":" 102 ":" 103 ":" 104 ":" 105 ":" 106 ":" 107 ":" 108 ":" 109 ":" 110 ":" 111 ":" 112 ":" 113 ":" 114 ":" 115 ":" 116 ":" 117 ":" 118 ":" 119 ":" 120 ":" 121 ":" 122 ":" 123 ":" 124 ":" 125 ":" 126 ":" 127 ":" 128 ":" 129 ":" 130 ":" 131 ":" 132 ":" 133 ":" 134 ":" 135 ":" 136 ":" 137 ":" 138 ":" 139 ":" 140 ":" 141 ":" 142 ":" 143 ":" 144 ":" 145 ":" 146 ":" 147 ":" 148 ":" 149 ":" 150 ":" 151 ":" 152 ":" 153 ":" 154 ":" 155 ":" 156 ":" 157 ":" 158 ":" 159 ":" 160 ":" 161 ":" 162 ":" 163 ":" 164 ":" 165 ":" 166 ":" 167 ":" 168 ":" 169 ":" 170 ":" 171 ":" 172 ":" 173 ":" 174 ":" 175 ":" 176 ":" 177 ":" 178 ":" 179 ":" 180 ":" 181 ":" 182 ":" 183 ":" 184 ":" 185 ":" 186 ":" 187 ":" 188 ":" 189 ":" 190 ":" 191 ":" 192 ":" 193 ":" 194 ":" 195 ":" 196 ":" 197 ":" 198 ":" 199 ":" 200 ":" 201 ":" 202 ":" 203 ":" 204 ":" 205 ":" 206 ":" 207 ":" 208 ":" 209 ":" 210 ":" 211 ":" 212 ":" 213 ":" 214 ":" 215 ":" 216 ":" 217 ":" 218 ":" 219 ":" 220 ":" 221 ":" 222 ":" 223 ":" 224 ":" 225 ":" 226 ":" 227 ":" 228 ":" 229 ":" 230 ":" 231 ":" 232 ":" 233 ":" 234 ":" 235 ":" 236 ":" 237 ":" 238 ":" 239 ":" 240 ":" 241 ":" 242 ":" 243 ":" 244 ":" 245 ":" 246 ":" 247 ":" 248 ":" 249 ":" 250 ":" 251 ":" 252 ":" 253 ":" 254 ":" 255 ":" ;
VAL_ 403 EPS_CONA_QF 0 "0b:EPS Control Angle signal available" 1 "1b:EPS Control Angle signal not available" ;
VAL_ 403 EPS_CNT_ST2 0 ":" 1 ":" 2 ":" 3 ":" 4 ":" 5 ":" 6 ":" 7 ":" 8 ":" 9 ":" 10 ":" 11 ":" 12 ":" 13 ":" 14 ":" 15 ":" ;
VAL_ 403 EPS_SUM_ST2 0 ":" 1 ":" 2 ":" 3 ":" 4 ":" 5 ":" 6 ":" 7 ":" 8 ":" 9 ":" 10 ":" 11 ":" 12 ":" 13 ":" 14 ":" 15 ":" 16 ":" 17 ":" 18 ":" 19 ":" 20 ":" 21 ":" 22 ":" 23 ":" 24 ":" 25 ":" 26 ":" 27 ":" 28 ":" 29 ":" 30 ":" 31 ":" 32 ":" 33 ":" 34 ":" 35 ":" 36 ":" 37 ":" 38 ":" 39 ":" 40 ":" 41 ":" 42 ":" 43 ":" 44 ":" 45 ":" 46 ":" 47 ":" 48 ":" 49 ":" 50 ":" 51 ":" 52 ":" 53 ":" 54 ":" 55 ":" 56 ":" 57 ":" 58 ":" 59 ":" 60 ":" 61 ":" 62 ":" 63 ":" 64 ":" 65 ":" 66 ":" 67 ":" 68 ":" 69 ":" 70 ":" 71 ":" 72 ":" 73 ":" 74 ":" 75 ":" 76 ":" 77 ":" 78 ":" 79 ":" 80 ":" 81 ":" 82 ":" 83 ":" 84 ":" 85 ":" 86 ":" 87 ":" 88 ":" 89 ":" 90 ":" 91 ":" 92 ":" 93 ":" 94 ":" 95 ":" 96 ":" 97 ":" 98 ":" 99 ":" 100 ":" 101 ":" 102 ":" 103 ":" 104 ":" 105 ":" 106 ":" 107 ":" 108 ":" 109 ":" 110 ":" 111 ":" 112 ":" 113 ":" 114 ":" 115 ":" 116 ":" 117 ":" 118 ":" 119 ":" 120 ":" 121 ":" 122 ":" 123 ":" 124 ":" 125 ":" 126 ":" 127 ":" 128 ":" 129 ":" 130 ":" 131 ":" 132 ":" 133 ":" 134 ":" 135 ":" 136 ":" 137 ":" 138 ":" 139 ":" 140 ":" 141 ":" 142 ":" 143 ":" 144 ":" 145 ":" 146 ":" 147 ":" 148 ":" 149 ":" 150 ":" 151 ":" 152 ":" 153 ":" 154 ":" 155 ":" 156 ":" 157 ":" 158 ":" 159 ":" 160 ":" 161 ":" 162 ":" 163 ":" 164 ":" 165 ":" 166 ":" 167 ":" 168 ":" 169 ":" 170 ":" 171 ":" 172 ":" 173 ":" 174 ":" 175 ":" 176 ":" 177 ":" 178 ":" 179 ":" 180 ":" 181 ":" 182 ":" 183 ":" 184 ":" 185 ":" 186 ":" 187 ":" 188 ":" 189 ":" 190 ":" 191 ":" 192 ":" 193 ":" 194 ":" 195 ":" 196 ":" 197 ":" 198 ":" 199 ":" 200 ":" 201 ":" 202 ":" 203 ":" 204 ":" 205 ":" 206 ":" 207 ":" 208 ":" 209 ":" 210 ":" 211 ":" 212 ":" 213 ":" 214 ":" 215 ":" 216 ":" 217 ":" 218 ":" 219 ":" 220 ":" 221 ":" 222 ":" 223 ":" 224 ":" 225 ":" 226 ":" 227 ":" 228 ":" 229 ":" 230 ":" 231 ":" 232 ":" 233 ":" 234 ":" 235 ":" 236 ":" 237 ":" 238 ":" 239 ":" 240 ":" 241 ":" 242 ":" 243 ":" 244 ":" 245 ":" 246 ":" 247 ":" 248 ":" 249 ":" 250 ":" 251 ":" 252 ":" 253 ":" 254 ":" 255 ":" ;
VAL_ 682 ADAS_PTC_STATUS_CHA 0 "00b:OFF" 1 "01b:ACC Protocal" 2 "10b:APA Protocal" 3 "11b:reserve" ;
VAL_ 682 SIGNAL_SOURCING_CHA 0 "00b:no signal" 1 "01b:AEB operation" 2 "10b:EAPM operation" 3 "11b:invalid" ;
VAL_ 682 AEB_ENBL_CHA 0 "0b:AEB not Enable" 1 "1b:AEB Enable" ;
VAL_ 682 AEB_STATUS_CHA 0 "0b:AEB not operation" 1 "1b:AEB operation" ;
VAL_ 682 AEB_ALIVE_CHA 0 "0b:abnormal" 1 "1b:normal" ;
VAL_ 682 PREFILL_ENBL_CHA 0 "0b:Prefill not Enable" 1 "1b:Prefill Enable" ;
VAL_ 682 PREFILL_STATUS_CHA 0 "0b:Prefill not operation" 1 "1b:Prefill operation" ;
VAL_ 682 PREFILL_ALIVE_CHA 0 "0b:abnormal" 1 "1b:normal" ;
VAL_ 682 ABA_ENBL_CHA 0 "0b:ABA not Enable" 1 "1b:ABA Enable" ;
VAL_ 682 ABA_STATUS_CHA 0 "0b:ABA not operation" 1 "1b:ABA operation" ;
VAL_ 682 ABA_ALIVE_CHA 0 "0b:abnormal" 1 "1b:normal" ;
VAL_ 682 AWB_ENBL_CHA 0 "0b:AWB not Enable" 1 "1b:AWB Enable" ;
VAL_ 682 AWB_STATUS_CHA 0 "0b:AWB not operation" 1 "1b:AWB operation" ;
VAL_ 682 AWB_ALIVE_CHA 0 "0b:abnormal" 1 "1b:normal" ;
VAL_ 682 ACC_CDD_ENBL_CHA 0 "0b:ACC_CDD not Enable" 1 "1b:ACC_CDD Enable" ;
VAL_ 682 ACC_CDD_STATUS_CHA 0 "0b:ACC_CDD not operation" 1 "1b:ACC_CDD operation(pressure on)" ;
VAL_ 682 ACC_CDD_ALIVE_CHA 0 "0b:abnormal" 1 "1b:normal" ;
VAL_ 682 ACC_CDD_TEMP_CHA 0 "0b:not off" 1 "1b:off" ;
VAL_ 682 WCBF_EXIST_CHA 0 "0b:No brake force" 1 "1b:Brake force exists" ;
VAL_ 682 VEH_STD_STILL_CHA 0 "00b:Vehicle is not standstill" 1 "01b:Vehicle is standstill" 2 "10b:Reserved" 3 "11b:Invalid" ;
VAL_ 682 MSG_CNT_BAM_CHA 0 ":" 1 ":" 2 ":" 3 ":" 4 ":" 5 ":" 6 ":" 7 ":" 8 ":" 9 ":" 10 ":" 11 ":" 12 ":" 13 ":" 14 ":" 15 ":" ;
VAL_ 682 CHKSUM_BAM_CHA 0 ":" 1 ":" 2 ":" 3 ":" 4 ":" 5 ":" 6 ":" 7 ":" 8 ":" 9 ":" 10 ":" 11 ":" 12 ":" 13 ":" 14 ":" 15 ":" 16 ":" 17 ":" 18 ":" 19 ":" 20 ":" 21 ":" 22 ":" 23 ":" 24 ":" 25 ":" 26 ":" 27 ":" 28 ":" 29 ":" 30 ":" 31 ":" 32 ":" 33 ":" 34 ":" 35 ":" 36 ":" 37 ":" 38 ":" 39 ":" 40 ":" 41 ":" 42 ":" 43 ":" 44 ":" 45 ":" 46 ":" 47 ":" 48 ":" 49 ":" 50 ":" 51 ":" 52 ":" 53 ":" 54 ":" 55 ":" 56 ":" 57 ":" 58 ":" 59 ":" 60 ":" 61 ":" 62 ":" 63 ":" 64 ":" 65 ":" 66 ":" 67 ":" 68 ":" 69 ":" 70 ":" 71 ":" 72 ":" 73 ":" 74 ":" 75 ":" 76 ":" 77 ":" 78 ":" 79 ":" 80 ":" 81 ":" 82 ":" 83 ":" 84 ":" 85 ":" 86 ":" 87 ":" 88 ":" 89 ":" 90 ":" 91 ":" 92 ":" 93 ":" 94 ":" 95 ":" 96 ":" 97 ":" 98 ":" 99 ":" 100 ":" 101 ":" 102 ":" 103 ":" 104 ":" 105 ":" 106 ":" 107 ":" 108 ":" 109 ":" 110 ":" 111 ":" 112 ":" 113 ":" 114 ":" 115 ":" 116 ":" 117 ":" 118 ":" 119 ":" 120 ":" 121 ":" 122 ":" 123 ":" 124 ":" 125 ":" 126 ":" 127 ":" 128 ":" 129 ":" 130 ":" 131 ":" 132 ":" 133 ":" 134 ":" 135 ":" 136 ":" 137 ":" 138 ":" 139 ":" 140 ":" 141 ":" 142 ":" 143 ":" 144 ":" 145 ":" 146 ":" 147 ":" 148 ":" 149 ":" 150 ":" 151 ":" 152 ":" 153 ":" 154 ":" 155 ":" 156 ":" 157 ":" 158 ":" 159 ":" 160 ":" 161 ":" 162 ":" 163 ":" 164 ":" 165 ":" 166 ":" 167 ":" 168 ":" 169 ":" 170 ":" 171 ":" 172 ":" 173 ":" 174 ":" 175 ":" 176 ":" 177 ":" 178 ":" 179 ":" 180 ":" 181 ":" 182 ":" 183 ":" 184 ":" 185 ":" 186 ":" 187 ":" 188 ":" 189 ":" 190 ":" 191 ":" 192 ":" 193 ":" 194 ":" 195 ":" 196 ":" 197 ":" 198 ":" 199 ":" 200 ":" 201 ":" 202 ":" 203 ":" 204 ":" 205 ":" 206 ":" 207 ":" 208 ":" 209 ":" 210 ":" 211 ":" 212 ":" 213 ":" 214 ":" 215 ":" 216 ":" 217 ":" 218 ":" 219 ":" 220 ":" 221 ":" 222 ":" 223 ":" 224 ":" 225 ":" 226 ":" 227 ":" 228 ":" 229 ":" 230 ":" 231 ":" 232 ":" 233 ":" 234 ":" 235 ":" 236 ":" 237 ":" 238 ":" 239 ":" 240 ":" 241 ":" 242 ":" 243 ":" 244 ":" 245 ":" 246 ":" 247 ":" 248 ":" 249 ":" 250 ":" 251 ":" 252 ":" 253 ":" 254 ":" 255 ":" ;
VAL_ 459 MbRgnTrgtWhl 0 ":" 1 ":" 2 ":" 3 ":" 4 ":" 5 ":" 6 ":" 7 ":" 8 ":" 9 ":" 10 ":" 11 ":" 12 ":" 13 ":" 14 ":" 15 ":" 16 ":" 17 ":" 18 ":" 19 ":" 20 ":" 21 ":" 22 ":" 23 ":" 24 ":" 25 ":" 26 ":" 27 ":" 28 ":" 29 ":" 30 ":" 31 ":" 32 ":" 33 ":" 34 ":" 35 ":" 36 ":" 37 ":" 38 ":" 39 ":" 40 ":" 41 ":" 42 ":" 43 ":" 44 ":" 45 ":" 46 ":" 47 ":" 48 ":" 49 ":" 50 ":" 51 ":" 52 ":" 53 ":" 54 ":" 55 ":" 56 ":" 57 ":" 58 ":" 59 ":" 60 ":" 61 ":" 62 ":" 63 ":" 64 ":" 65 ":" 66 ":" 67 ":" 68 ":" 69 ":" 70 ":" 71 ":" 72 ":" 73 ":" 74 ":" 75 ":" 76 ":" 77 ":" 78 ":" 79 ":" 80 ":" 81 ":" 82 ":" 83 ":" 84 ":" 85 ":" 86 ":" 87 ":" 88 ":" 89 ":" 90 ":" 91 ":" 92 ":" 93 ":" 94 ":" 95 ":" 96 ":" 97 ":" 98 ":" 99 ":" 100 ":" 101 ":" 102 ":" 103 ":" 104 ":" 105 ":" 106 ":" 107 ":" 108 ":" 109 ":" 110 ":" 111 ":" 112 ":" 113 ":" 114 ":" 115 ":" 116 ":" 117 ":" 118 ":" 119 ":" 120 ":" 121 ":" 122 ":" 123 ":" 124 ":" 125 ":" 126 ":" 127 ":" 128 ":" 129 ":" 130 ":" 131 ":" 132 ":" 133 ":" 134 ":" 135 ":" 136 ":" 137 ":" 138 ":" 139 ":" 140 ":" 141 ":" 142 ":" 143 ":" 144 ":" 145 ":" 146 ":" 147 ":" 148 ":" 149 ":" 150 ":" 151 ":" 152 ":" 153 ":" 154 ":" 155 ":" 156 ":" 157 ":" 158 ":" 159 ":" 160 ":" 161 ":" 162 ":" 163 ":" 164 ":" 165 ":" 166 ":" 167 ":" 168 ":" 169 ":" 170 ":" 171 ":" 172 ":" 173 ":" 174 ":" 175 ":" 176 ":" 177 ":" 178 ":" 179 ":" 180 ":" 181 ":" 182 ":" 183 ":" 184 ":" 185 ":" 186 ":" 187 ":" 188 ":" 189 ":" 190 ":" 191 ":" 192 ":" 193 ":" 194 ":" 195 ":" 196 ":" 197 ":" 198 ":" 199 ":" 200 ":" 201 ":" 202 ":" 203 ":" 204 ":" 205 ":" 206 ":" 207 ":" 208 ":" 209 ":" 210 ":" 211 ":" 212 ":" 213 ":" 214 ":" 215 ":" 216 ":" 217 ":" 218 ":" 219 ":" 220 ":" 221 ":" 222 ":" 223 ":" 224 ":" 225 ":" 226 ":" 227 ":" 228 ":" 229 ":" 230 ":" 231 ":" 232 ":" 233 ":" 234 ":" 235 ":" 236 ":" 237 ":" 238 ":" 239 ":" 240 ":" 241 ":" 242 ":" 243 ":" 244 ":" 245 ":" 246 ":" 247 ":" 248 ":" 249 ":" 250 ":" 251 ":" 252 ":" 253 ":" 254 ":" 255 ":" ;
VAL_ 459 MbRgnTrgtWhlQu 0 "00b:NotIntialized" 1 "01b:Normal" 2 "10b:Faulty" 3 "11b:Not used" ;
VAL_ 459 RBSACT 0 "0b:RBS not in regulation" 1 "1b:RBS in regulation" ;
VAL_ 459 RBSFAIL 0 "0b:RBS not malfunction (normal)" 1 "1b:RBS malfunction" ;
VAL_ 459 MSGCNTR_IBC 0 ":" 1 ":" 2 ":" 3 ":" 4 ":" 5 ":" 6 ":" 7 ":" 8 ":" 9 ":" 10 ":" 11 ":" 12 ":" 13 ":" 14 ":" 15 ":" ;
VAL_ 459 CHKSUM_BD 0 ":" 1 ":" 2 ":" 3 ":" 4 ":" 5 ":" 6 ":" 7 ":" 8 ":" 9 ":" 10 ":" 11 ":" 12 ":" 13 ":" 14 ":" 15 ":" 16 ":" 17 ":" 18 ":" 19 ":" 20 ":" 21 ":" 22 ":" 23 ":" 24 ":" 25 ":" 26 ":" 27 ":" 28 ":" 29 ":" 30 ":" 31 ":" 32 ":" 33 ":" 34 ":" 35 ":" 36 ":" 37 ":" 38 ":" 39 ":" 40 ":" 41 ":" 42 ":" 43 ":" 44 ":" 45 ":" 46 ":" 47 ":" 48 ":" 49 ":" 50 ":" 51 ":" 52 ":" 53 ":" 54 ":" 55 ":" 56 ":" 57 ":" 58 ":" 59 ":" 60 ":" 61 ":" 62 ":" 63 ":" 64 ":" 65 ":" 66 ":" 67 ":" 68 ":" 69 ":" 70 ":" 71 ":" 72 ":" 73 ":" 74 ":" 75 ":" 76 ":" 77 ":" 78 ":" 79 ":" 80 ":" 81 ":" 82 ":" 83 ":" 84 ":" 85 ":" 86 ":" 87 ":" 88 ":" 89 ":" 90 ":" 91 ":" 92 ":" 93 ":" 94 ":" 95 ":" 96 ":" 97 ":" 98 ":" 99 ":" 100 ":" 101 ":" 102 ":" 103 ":" 104 ":" 105 ":" 106 ":" 107 ":" 108 ":" 109 ":" 110 ":" 111 ":" 112 ":" 113 ":" 114 ":" 115 ":" 116 ":" 117 ":" 118 ":" 119 ":" 120 ":" 121 ":" 122 ":" 123 ":" 124 ":" 125 ":" 126 ":" 127 ":" 128 ":" 129 ":" 130 ":" 131 ":" 132 ":" 133 ":" 134 ":" 135 ":" 136 ":" 137 ":" 138 ":" 139 ":" 140 ":" 141 ":" 142 ":" 143 ":" 144 ":" 145 ":" 146 ":" 147 ":" 148 ":" 149 ":" 150 ":" 151 ":" 152 ":" 153 ":" 154 ":" 155 ":" 156 ":" 157 ":" 158 ":" 159 ":" 160 ":" 161 ":" 162 ":" 163 ":" 164 ":" 165 ":" 166 ":" 167 ":" 168 ":" 169 ":" 170 ":" 171 ":" 172 ":" 173 ":" 174 ":" 175 ":" 176 ":" 177 ":" 178 ":" 179 ":" 180 ":" 181 ":" 182 ":" 183 ":" 184 ":" 185 ":" 186 ":" 187 ":" 188 ":" 189 ":" 190 ":" 191 ":" 192 ":" 193 ":" 194 ":" 195 ":" 196 ":" 197 ":" 198 ":" 199 ":" 200 ":" 201 ":" 202 ":" 203 ":" 204 ":" 205 ":" 206 ":" 207 ":" 208 ":" 209 ":" 210 ":" 211 ":" 212 ":" 213 ":" 214 ":" 215 ":" 216 ":" 217 ":" 218 ":" 219 ":" 220 ":" 221 ":" 222 ":" 223 ":" 224 ":" 225 ":" 226 ":" 227 ":" 228 ":" 229 ":" 230 ":" 231 ":" 232 ":" 233 ":" 234 ":" 235 ":" 236 ":" 237 ":" 238 ":" 239 ":" 240 ":" 241 ":" 242 ":" 243 ":" 244 ":" 245 ":" 246 ":" 247 ":" 248 ":" 249 ":" 250 ":" 251 ":" 252 ":" 253 ":" 254 ":" 255 ":" ;
VAL_ 581 VDCFAIL 0 "0b:no VDC(ESP) malfunction" 1 "1b:VDC(ESP) malfunction" ;
VAL_ 581 OFF_SW 0 "0b:VDC(ESP) available" 1 "1b:VDC(ESP) disabled by the driver" ;
VAL_ 581 TCSACT 0 "0b:no TCS(ASR) regulation" 1 "1b:TSC(ASR) in regulation" ;
VAL_ 581 VDCACT 0 "0b:no VDC(AYC) regulation" 1 "1b:VDC(AYC) in regulation" ;
VAL_ 581 MSRACT 0 "0b:no MSR regulation" 1 "1b:MSR regulation" ;
VAL_ 581 TCSFAIL 0 "0b:no TCS(ASR) malfunction" 1 "1b:TCS(ASR) malfunction" ;
VAL_ 581 MSGCNTRR1 0 ":" 1 ":" 2 ":" 3 ":" 4 ":" 5 ":" 6 ":" 7 ":" 8 ":" 9 ":" 10 ":" 11 ":" 12 ":" 13 ":" 14 ":" 15 ":" ;
VAL_ 644 WRFR_CHA 0 ":" 1 ":" 2 ":" 3 ":" 4 ":" 5 ":" 6 ":" 7 ":" 8 ":" 9 ":" 10 ":" 11 ":" 12 ":" 13 ":" 14 ":" 15 ":" 16 ":" 17 ":" 18 ":" 19 ":" 20 ":" 21 ":" 22 ":" 23 ":" 24 ":" 25 ":" 26 ":" 27 ":" 28 ":" 29 ":" 30 ":" 31 ":" 32 ":" 33 ":" 34 ":" 35 ":" 36 ":" 37 ":" 38 ":" 39 ":" 40 ":" 41 ":" 42 ":" 43 ":" 44 ":" 45 ":" 46 ":" 47 ":" 48 ":" 49 ":" 50 ":" 51 ":" 52 ":" 53 ":" 54 ":" 55 ":" 56 ":" 57 ":" 58 ":" 59 ":" 60 ":" 61 ":" 62 ":" 63 ":" 64 ":" 65 ":" 66 ":" 67 ":" 68 ":" 69 ":" 70 ":" 71 ":" 72 ":" 73 ":" 74 ":" 75 ":" 76 ":" 77 ":" 78 ":" 79 ":" 80 ":" 81 ":" 82 ":" 83 ":" 84 ":" 85 ":" 86 ":" 87 ":" 88 ":" 89 ":" 90 ":" 91 ":" 92 ":" 93 ":" 94 ":" 95 ":" 96 ":" 97 ":" 98 ":" 99 ":" 100 ":" 101 ":" 102 ":" 103 ":" 104 ":" 105 ":" 106 ":" 107 ":" 108 ":" 109 ":" 110 ":" 111 ":" 112 ":" 113 ":" 114 ":" 115 ":" 116 ":" 117 ":" 118 ":" 119 ":" 120 ":" 121 ":" 122 ":" 123 ":" 124 ":" 125 ":" 126 ":" 127 ":" 128 ":" 129 ":" 130 ":" 131 ":" 132 ":" 133 ":" 134 ":" 135 ":" 136 ":" 137 ":" 138 ":" 139 ":" 140 ":" 141 ":" 142 ":" 143 ":" 144 ":" 145 ":" 146 ":" 147 ":" 148 ":" 149 ":" 150 ":" 151 ":" 152 ":" 153 ":" 154 ":" 155 ":" 156 ":" 157 ":" 158 ":" 159 ":" 160 ":" 161 ":" 162 ":" 163 ":" 164 ":" 165 ":" 166 ":" 167 ":" 168 ":" 169 ":" 170 ":" 171 ":" 172 ":" 173 ":" 174 ":" 175 ":" 176 ":" 177 ":" 178 ":" 179 ":" 180 ":" 181 ":" 182 ":" 183 ":" 184 ":" 185 ":" 186 ":" 187 ":" 188 ":" 189 ":" 190 ":" 191 ":" 192 ":" 193 ":" 194 ":" 195 ":" 196 ":" 197 ":" 198 ":" 199 ":" 200 ":" 201 ":" 202 ":" 203 ":" 204 ":" 205 ":" 206 ":" 207 ":" 208 ":" 209 ":" 210 ":" 211 ":" 212 ":" 213 ":" 214 ":" 215 ":" 216 ":" 217 ":" 218 ":" 219 ":" 220 ":" 221 ":" 222 ":" 223 ":" 224 ":" 225 ":" 226 ":" 227 ":" 228 ":" 229 ":" 230 ":" 231 ":" 232 ":" 233 ":" 234 ":" 235 ":" 236 ":" 237 ":" 238 ":" 239 ":" 240 ":" 241 ":" 242 ":" 243 ":" 244 ":" 245 ":" 246 ":" 247 ":" 248 ":" 249 ":" 250 ":" 251 ":" 252 ":" 253 ":" 254 ":" 255 ":" ;
VAL_ 644 WRFL_CHA 0 ":" 1 ":" 2 ":" 3 ":" 4 ":" 5 ":" 6 ":" 7 ":" 8 ":" 9 ":" 10 ":" 11 ":" 12 ":" 13 ":" 14 ":" 15 ":" 16 ":" 17 ":" 18 ":" 19 ":" 20 ":" 21 ":" 22 ":" 23 ":" 24 ":" 25 ":" 26 ":" 27 ":" 28 ":" 29 ":" 30 ":" 31 ":" 32 ":" 33 ":" 34 ":" 35 ":" 36 ":" 37 ":" 38 ":" 39 ":" 40 ":" 41 ":" 42 ":" 43 ":" 44 ":" 45 ":" 46 ":" 47 ":" 48 ":" 49 ":" 50 ":" 51 ":" 52 ":" 53 ":" 54 ":" 55 ":" 56 ":" 57 ":" 58 ":" 59 ":" 60 ":" 61 ":" 62 ":" 63 ":" 64 ":" 65 ":" 66 ":" 67 ":" 68 ":" 69 ":" 70 ":" 71 ":" 72 ":" 73 ":" 74 ":" 75 ":" 76 ":" 77 ":" 78 ":" 79 ":" 80 ":" 81 ":" 82 ":" 83 ":" 84 ":" 85 ":" 86 ":" 87 ":" 88 ":" 89 ":" 90 ":" 91 ":" 92 ":" 93 ":" 94 ":" 95 ":" 96 ":" 97 ":" 98 ":" 99 ":" 100 ":" 101 ":" 102 ":" 103 ":" 104 ":" 105 ":" 106 ":" 107 ":" 108 ":" 109 ":" 110 ":" 111 ":" 112 ":" 113 ":" 114 ":" 115 ":" 116 ":" 117 ":" 118 ":" 119 ":" 120 ":" 121 ":" 122 ":" 123 ":" 124 ":" 125 ":" 126 ":" 127 ":" 128 ":" 129 ":" 130 ":" 131 ":" 132 ":" 133 ":" 134 ":" 135 ":" 136 ":" 137 ":" 138 ":" 139 ":" 140 ":" 141 ":" 142 ":" 143 ":" 144 ":" 145 ":" 146 ":" 147 ":" 148 ":" 149 ":" 150 ":" 151 ":" 152 ":" 153 ":" 154 ":" 155 ":" 156 ":" 157 ":" 158 ":" 159 ":" 160 ":" 161 ":" 162 ":" 163 ":" 164 ":" 165 ":" 166 ":" 167 ":" 168 ":" 169 ":" 170 ":" 171 ":" 172 ":" 173 ":" 174 ":" 175 ":" 176 ":" 177 ":" 178 ":" 179 ":" 180 ":" 181 ":" 182 ":" 183 ":" 184 ":" 185 ":" 186 ":" 187 ":" 188 ":" 189 ":" 190 ":" 191 ":" 192 ":" 193 ":" 194 ":" 195 ":" 196 ":" 197 ":" 198 ":" 199 ":" 200 ":" 201 ":" 202 ":" 203 ":" 204 ":" 205 ":" 206 ":" 207 ":" 208 ":" 209 ":" 210 ":" 211 ":" 212 ":" 213 ":" 214 ":" 215 ":" 216 ":" 217 ":" 218 ":" 219 ":" 220 ":" 221 ":" 222 ":" 223 ":" 224 ":" 225 ":" 226 ":" 227 ":" 228 ":" 229 ":" 230 ":" 231 ":" 232 ":" 233 ":" 234 ":" 235 ":" 236 ":" 237 ":" 238 ":" 239 ":" 240 ":" 241 ":" 242 ":" 243 ":" 244 ":" 245 ":" 246 ":" 247 ":" 248 ":" 249 ":" 250 ":" 251 ":" 252 ":" 253 ":" 254 ":" 255 ":" ;
VAL_ 644 VSO_CHA_FWS 0 ":" 1 ":" 2 ":" 3 ":" 4 ":" 5 ":" 6 ":" 7 ":" 8 ":" 9 ":" 10 ":" 11 ":" 12 ":" 13 ":" 14 ":" 15 ":" 16 ":" 17 ":" 18 ":" 19 ":" 20 ":" 21 ":" 22 ":" 23 ":" 24 ":" 25 ":" 26 ":" 27 ":" 28 ":" 29 ":" 30 ":" 31 ":" 32 ":" 33 ":" 34 ":" 35 ":" 36 ":" 37 ":" 38 ":" 39 ":" 40 ":" 41 ":" 42 ":" 43 ":" 44 ":" 45 ":" 46 ":" 47 ":" 48 ":" 49 ":" 50 ":" 51 ":" 52 ":" 53 ":" 54 ":" 55 ":" 56 ":" 57 ":" 58 ":" 59 ":" 60 ":" 61 ":" 62 ":" 63 ":" 64 ":" 65 ":" 66 ":" 67 ":" 68 ":" 69 ":" 70 ":" 71 ":" 72 ":" 73 ":" 74 ":" 75 ":" 76 ":" 77 ":" 78 ":" 79 ":" 80 ":" 81 ":" 82 ":" 83 ":" 84 ":" 85 ":" 86 ":" 87 ":" 88 ":" 89 ":" 90 ":" 91 ":" 92 ":" 93 ":" 94 ":" 95 ":" 96 ":" 97 ":" 98 ":" 99 ":" 100 ":" 101 ":" 102 ":" 103 ":" 104 ":" 105 ":" 106 ":" 107 ":" 108 ":" 109 ":" 110 ":" 111 ":" 112 ":" 113 ":" 114 ":" 115 ":" 116 ":" 117 ":" 118 ":" 119 ":" 120 ":" 121 ":" 122 ":" 123 ":" 124 ":" 125 ":" 126 ":" 127 ":" 128 ":" 129 ":" 130 ":" 131 ":" 132 ":" 133 ":" 134 ":" 135 ":" 136 ":" 137 ":" 138 ":" 139 ":" 140 ":" 141 ":" 142 ":" 143 ":" 144 ":" 145 ":" 146 ":" 147 ":" 148 ":" 149 ":" 150 ":" 151 ":" 152 ":" 153 ":" 154 ":" 155 ":" 156 ":" 157 ":" 158 ":" 159 ":" 160 ":" 161 ":" 162 ":" 163 ":" 164 ":" 165 ":" 166 ":" 167 ":" 168 ":" 169 ":" 170 ":" 171 ":" 172 ":" 173 ":" 174 ":" 175 ":" 176 ":" 177 ":" 178 ":" 179 ":" 180 ":" 181 ":" 182 ":" 183 ":" 184 ":" 185 ":" 186 ":" 187 ":" 188 ":" 189 ":" 190 ":" 191 ":" 192 ":" 193 ":" 194 ":" 195 ":" 196 ":" 197 ":" 198 ":" 199 ":" 200 ":" 201 ":" 202 ":" 203 ":" 204 ":" 205 ":" 206 ":" 207 ":" 208 ":" 209 ":" 210 ":" 211 ":" 212 ":" 213 ":" 214 ":" 215 ":" 216 ":" 217 ":" 218 ":" 219 ":" 220 ":" 221 ":" 222 ":" 223 ":" 224 ":" 225 ":" 226 ":" 227 ":" 228 ":" 229 ":" 230 ":" 231 ":" 232 ":" 233 ":" 234 ":" 235 ":" 236 ":" 237 ":" 238 ":" 239 ":" 240 ":" 241 ":" 242 ":" 243 ":" 244 ":" 245 ":" 246 ":" 247 ":" 248 ":" 249 ":" 250 ":" 251 ":" 252 ":" 253 ":" 254 ":" 255 ":" ;
VAL_ 644 MSGCOUNT_FWSF_CHA 0 ":" 1 ":" 2 ":" 3 ":" 4 ":" 5 ":" 6 ":" 7 ":" 8 ":" 9 ":" 10 ":" 11 ":" 12 ":" 13 ":" 14 ":" 15 ":" 16 ":" 17 ":" 18 ":" 19 ":" 20 ":" 21 ":" 22 ":" 23 ":" 24 ":" 25 ":" 26 ":" 27 ":" 28 ":" 29 ":" 30 ":" 31 ":" 32 ":" 33 ":" 34 ":" 35 ":" 36 ":" 37 ":" 38 ":" 39 ":" 40 ":" 41 ":" 42 ":" 43 ":" 44 ":" 45 ":" 46 ":" 47 ":" 48 ":" 49 ":" 50 ":" 51 ":" 52 ":" 53 ":" 54 ":" 55 ":" 56 ":" 57 ":" 58 ":" 59 ":" 60 ":" 61 ":" 62 ":" 63 ":" 64 ":" 65 ":" 66 ":" 67 ":" 68 ":" 69 ":" 70 ":" 71 ":" 72 ":" 73 ":" 74 ":" 75 ":" 76 ":" 77 ":" 78 ":" 79 ":" 80 ":" 81 ":" 82 ":" 83 ":" 84 ":" 85 ":" 86 ":" 87 ":" 88 ":" 89 ":" 90 ":" 91 ":" 92 ":" 93 ":" 94 ":" 95 ":" 96 ":" 97 ":" 98 ":" 99 ":" 100 ":" 101 ":" 102 ":" 103 ":" 104 ":" 105 ":" 106 ":" 107 ":" 108 ":" 109 ":" 110 ":" 111 ":" 112 ":" 113 ":" 114 ":" 115 ":" 116 ":" 117 ":" 118 ":" 119 ":" 120 ":" 121 ":" 122 ":" 123 ":" 124 ":" 125 ":" 126 ":" 127 ":" 128 ":" 129 ":" 130 ":" 131 ":" 132 ":" 133 ":" 134 ":" 135 ":" 136 ":" 137 ":" 138 ":" 139 ":" 140 ":" 141 ":" 142 ":" 143 ":" 144 ":" 145 ":" 146 ":" 147 ":" 148 ":" 149 ":" 150 ":" 151 ":" 152 ":" 153 ":" 154 ":" 155 ":" 156 ":" 157 ":" 158 ":" 159 ":" 160 ":" 161 ":" 162 ":" 163 ":" 164 ":" 165 ":" 166 ":" 167 ":" 168 ":" 169 ":" 170 ":" 171 ":" 172 ":" 173 ":" 174 ":" 175 ":" 176 ":" 177 ":" 178 ":" 179 ":" 180 ":" 181 ":" 182 ":" 183 ":" 184 ":" 185 ":" 186 ":" 187 ":" 188 ":" 189 ":" 190 ":" 191 ":" 192 ":" 193 ":" 194 ":" 195 ":" 196 ":" 197 ":" 198 ":" 199 ":" 200 ":" 201 ":" 202 ":" 203 ":" 204 ":" 205 ":" 206 ":" 207 ":" 208 ":" 209 ":" 210 ":" 211 ":" 212 ":" 213 ":" 214 ":" 215 ":" 216 ":" 217 ":" 218 ":" 219 ":" 220 ":" 221 ":" 222 ":" 223 ":" 224 ":" 225 ":" 226 ":" 227 ":" 228 ":" 229 ":" 230 ":" 231 ":" 232 ":" 233 ":" 234 ":" 235 ":" 236 ":" 237 ":" 238 ":" 239 ":" 240 ":" 241 ":" 242 ":" 243 ":" 244 ":" 245 ":" 246 ":" 247 ":" 248 ":" 249 ":" 250 ":" 251 ":" 252 ":" 253 ":" 254 ":" 255 ":" ;
VAL_ 644 CHKSUMFR_FWSF_CHA 0 ":" 1 ":" 2 ":" 3 ":" 4 ":" 5 ":" 6 ":" 7 ":" 8 ":" 9 ":" 10 ":" 11 ":" 12 ":" 13 ":" 14 ":" 15 ":" 16 ":" 17 ":" 18 ":" 19 ":" 20 ":" 21 ":" 22 ":" 23 ":" 24 ":" 25 ":" 26 ":" 27 ":" 28 ":" 29 ":" 30 ":" 31 ":" 32 ":" 33 ":" 34 ":" 35 ":" 36 ":" 37 ":" 38 ":" 39 ":" 40 ":" 41 ":" 42 ":" 43 ":" 44 ":" 45 ":" 46 ":" 47 ":" 48 ":" 49 ":" 50 ":" 51 ":" 52 ":" 53 ":" 54 ":" 55 ":" 56 ":" 57 ":" 58 ":" 59 ":" 60 ":" 61 ":" 62 ":" 63 ":" 64 ":" 65 ":" 66 ":" 67 ":" 68 ":" 69 ":" 70 ":" 71 ":" 72 ":" 73 ":" 74 ":" 75 ":" 76 ":" 77 ":" 78 ":" 79 ":" 80 ":" 81 ":" 82 ":" 83 ":" 84 ":" 85 ":" 86 ":" 87 ":" 88 ":" 89 ":" 90 ":" 91 ":" 92 ":" 93 ":" 94 ":" 95 ":" 96 ":" 97 ":" 98 ":" 99 ":" 100 ":" 101 ":" 102 ":" 103 ":" 104 ":" 105 ":" 106 ":" 107 ":" 108 ":" 109 ":" 110 ":" 111 ":" 112 ":" 113 ":" 114 ":" 115 ":" 116 ":" 117 ":" 118 ":" 119 ":" 120 ":" 121 ":" 122 ":" 123 ":" 124 ":" 125 ":" 126 ":" 127 ":" 128 ":" 129 ":" 130 ":" 131 ":" 132 ":" 133 ":" 134 ":" 135 ":" 136 ":" 137 ":" 138 ":" 139 ":" 140 ":" 141 ":" 142 ":" 143 ":" 144 ":" 145 ":" 146 ":" 147 ":" 148 ":" 149 ":" 150 ":" 151 ":" 152 ":" 153 ":" 154 ":" 155 ":" 156 ":" 157 ":" 158 ":" 159 ":" 160 ":" 161 ":" 162 ":" 163 ":" 164 ":" 165 ":" 166 ":" 167 ":" 168 ":" 169 ":" 170 ":" 171 ":" 172 ":" 173 ":" 174 ":" 175 ":" 176 ":" 177 ":" 178 ":" 179 ":" 180 ":" 181 ":" 182 ":" 183 ":" 184 ":" 185 ":" 186 ":" 187 ":" 188 ":" 189 ":" 190 ":" 191 ":" 192 ":" 193 ":" 194 ":" 195 ":" 196 ":" 197 ":" 198 ":" 199 ":" 200 ":" 201 ":" 202 ":" 203 ":" 204 ":" 205 ":" 206 ":" 207 ":" 208 ":" 209 ":" 210 ":" 211 ":" 212 ":" 213 ":" 214 ":" 215 ":" 216 ":" 217 ":" 218 ":" 219 ":" 220 ":" 221 ":" 222 ":" 223 ":" 224 ":" 225 ":" 226 ":" 227 ":" 228 ":" 229 ":" 230 ":" 231 ":" 232 ":" 233 ":" 234 ":" 235 ":" 236 ":" 237 ":" 238 ":" 239 ":" 240 ":" 241 ":" 242 ":" 243 ":" 244 ":" 245 ":" 246 ":" 247 ":" 248 ":" 249 ":" 250 ":" 251 ":" 252 ":" 253 ":" 254 ":" 255 ":" ;
VAL_ 645 WRRR_CHA 0 ":" 1 ":" 2 ":" 3 ":" 4 ":" 5 ":" 6 ":" 7 ":" 8 ":" 9 ":" 10 ":" 11 ":" 12 ":" 13 ":" 14 ":" 15 ":" 16 ":" 17 ":" 18 ":" 19 ":" 20 ":" 21 ":" 22 ":" 23 ":" 24 ":" 25 ":" 26 ":" 27 ":" 28 ":" 29 ":" 30 ":" 31 ":" 32 ":" 33 ":" 34 ":" 35 ":" 36 ":" 37 ":" 38 ":" 39 ":" 40 ":" 41 ":" 42 ":" 43 ":" 44 ":" 45 ":" 46 ":" 47 ":" 48 ":" 49 ":" 50 ":" 51 ":" 52 ":" 53 ":" 54 ":" 55 ":" 56 ":" 57 ":" 58 ":" 59 ":" 60 ":" 61 ":" 62 ":" 63 ":" 64 ":" 65 ":" 66 ":" 67 ":" 68 ":" 69 ":" 70 ":" 71 ":" 72 ":" 73 ":" 74 ":" 75 ":" 76 ":" 77 ":" 78 ":" 79 ":" 80 ":" 81 ":" 82 ":" 83 ":" 84 ":" 85 ":" 86 ":" 87 ":" 88 ":" 89 ":" 90 ":" 91 ":" 92 ":" 93 ":" 94 ":" 95 ":" 96 ":" 97 ":" 98 ":" 99 ":" 100 ":" 101 ":" 102 ":" 103 ":" 104 ":" 105 ":" 106 ":" 107 ":" 108 ":" 109 ":" 110 ":" 111 ":" 112 ":" 113 ":" 114 ":" 115 ":" 116 ":" 117 ":" 118 ":" 119 ":" 120 ":" 121 ":" 122 ":" 123 ":" 124 ":" 125 ":" 126 ":" 127 ":" 128 ":" 129 ":" 130 ":" 131 ":" 132 ":" 133 ":" 134 ":" 135 ":" 136 ":" 137 ":" 138 ":" 139 ":" 140 ":" 141 ":" 142 ":" 143 ":" 144 ":" 145 ":" 146 ":" 147 ":" 148 ":" 149 ":" 150 ":" 151 ":" 152 ":" 153 ":" 154 ":" 155 ":" 156 ":" 157 ":" 158 ":" 159 ":" 160 ":" 161 ":" 162 ":" 163 ":" 164 ":" 165 ":" 166 ":" 167 ":" 168 ":" 169 ":" 170 ":" 171 ":" 172 ":" 173 ":" 174 ":" 175 ":" 176 ":" 177 ":" 178 ":" 179 ":" 180 ":" 181 ":" 182 ":" 183 ":" 184 ":" 185 ":" 186 ":" 187 ":" 188 ":" 189 ":" 190 ":" 191 ":" 192 ":" 193 ":" 194 ":" 195 ":" 196 ":" 197 ":" 198 ":" 199 ":" 200 ":" 201 ":" 202 ":" 203 ":" 204 ":" 205 ":" 206 ":" 207 ":" 208 ":" 209 ":" 210 ":" 211 ":" 212 ":" 213 ":" 214 ":" 215 ":" 216 ":" 217 ":" 218 ":" 219 ":" 220 ":" 221 ":" 222 ":" 223 ":" 224 ":" 225 ":" 226 ":" 227 ":" 228 ":" 229 ":" 230 ":" 231 ":" 232 ":" 233 ":" 234 ":" 235 ":" 236 ":" 237 ":" 238 ":" 239 ":" 240 ":" 241 ":" 242 ":" 243 ":" 244 ":" 245 ":" 246 ":" 247 ":" 248 ":" 249 ":" 250 ":" 251 ":" 252 ":" 253 ":" 254 ":" 255 ":" ;
VAL_ 645 WRRL_CHA 0 ":" 1 ":" 2 ":" 3 ":" 4 ":" 5 ":" 6 ":" 7 ":" 8 ":" 9 ":" 10 ":" 11 ":" 12 ":" 13 ":" 14 ":" 15 ":" 16 ":" 17 ":" 18 ":" 19 ":" 20 ":" 21 ":" 22 ":" 23 ":" 24 ":" 25 ":" 26 ":" 27 ":" 28 ":" 29 ":" 30 ":" 31 ":" 32 ":" 33 ":" 34 ":" 35 ":" 36 ":" 37 ":" 38 ":" 39 ":" 40 ":" 41 ":" 42 ":" 43 ":" 44 ":" 45 ":" 46 ":" 47 ":" 48 ":" 49 ":" 50 ":" 51 ":" 52 ":" 53 ":" 54 ":" 55 ":" 56 ":" 57 ":" 58 ":" 59 ":" 60 ":" 61 ":" 62 ":" 63 ":" 64 ":" 65 ":" 66 ":" 67 ":" 68 ":" 69 ":" 70 ":" 71 ":" 72 ":" 73 ":" 74 ":" 75 ":" 76 ":" 77 ":" 78 ":" 79 ":" 80 ":" 81 ":" 82 ":" 83 ":" 84 ":" 85 ":" 86 ":" 87 ":" 88 ":" 89 ":" 90 ":" 91 ":" 92 ":" 93 ":" 94 ":" 95 ":" 96 ":" 97 ":" 98 ":" 99 ":" 100 ":" 101 ":" 102 ":" 103 ":" 104 ":" 105 ":" 106 ":" 107 ":" 108 ":" 109 ":" 110 ":" 111 ":" 112 ":" 113 ":" 114 ":" 115 ":" 116 ":" 117 ":" 118 ":" 119 ":" 120 ":" 121 ":" 122 ":" 123 ":" 124 ":" 125 ":" 126 ":" 127 ":" 128 ":" 129 ":" 130 ":" 131 ":" 132 ":" 133 ":" 134 ":" 135 ":" 136 ":" 137 ":" 138 ":" 139 ":" 140 ":" 141 ":" 142 ":" 143 ":" 144 ":" 145 ":" 146 ":" 147 ":" 148 ":" 149 ":" 150 ":" 151 ":" 152 ":" 153 ":" 154 ":" 155 ":" 156 ":" 157 ":" 158 ":" 159 ":" 160 ":" 161 ":" 162 ":" 163 ":" 164 ":" 165 ":" 166 ":" 167 ":" 168 ":" 169 ":" 170 ":" 171 ":" 172 ":" 173 ":" 174 ":" 175 ":" 176 ":" 177 ":" 178 ":" 179 ":" 180 ":" 181 ":" 182 ":" 183 ":" 184 ":" 185 ":" 186 ":" 187 ":" 188 ":" 189 ":" 190 ":" 191 ":" 192 ":" 193 ":" 194 ":" 195 ":" 196 ":" 197 ":" 198 ":" 199 ":" 200 ":" 201 ":" 202 ":" 203 ":" 204 ":" 205 ":" 206 ":" 207 ":" 208 ":" 209 ":" 210 ":" 211 ":" 212 ":" 213 ":" 214 ":" 215 ":" 216 ":" 217 ":" 218 ":" 219 ":" 220 ":" 221 ":" 222 ":" 223 ":" 224 ":" 225 ":" 226 ":" 227 ":" 228 ":" 229 ":" 230 ":" 231 ":" 232 ":" 233 ":" 234 ":" 235 ":" 236 ":" 237 ":" 238 ":" 239 ":" 240 ":" 241 ":" 242 ":" 243 ":" 244 ":" 245 ":" 246 ":" 247 ":" 248 ":" 249 ":" 250 ":" 251 ":" 252 ":" 253 ":" 254 ":" 255 ":" ;
VAL_ 645 VCVT_CHA 0 ":" 1 ":" 2 ":" 3 ":" 4 ":" 5 ":" 6 ":" 7 ":" 8 ":" 9 ":" 10 ":" 11 ":" 12 ":" 13 ":" 14 ":" 15 ":" 16 ":" 17 ":" 18 ":" 19 ":" 20 ":" 21 ":" 22 ":" 23 ":" 24 ":" 25 ":" 26 ":" 27 ":" 28 ":" 29 ":" 30 ":" 31 ":" 32 ":" 33 ":" 34 ":" 35 ":" 36 ":" 37 ":" 38 ":" 39 ":" 40 ":" 41 ":" 42 ":" 43 ":" 44 ":" 45 ":" 46 ":" 47 ":" 48 ":" 49 ":" 50 ":" 51 ":" 52 ":" 53 ":" 54 ":" 55 ":" 56 ":" 57 ":" 58 ":" 59 ":" 60 ":" 61 ":" 62 ":" 63 ":" 64 ":" 65 ":" 66 ":" 67 ":" 68 ":" 69 ":" 70 ":" 71 ":" 72 ":" 73 ":" 74 ":" 75 ":" 76 ":" 77 ":" 78 ":" 79 ":" 80 ":" 81 ":" 82 ":" 83 ":" 84 ":" 85 ":" 86 ":" 87 ":" 88 ":" 89 ":" 90 ":" 91 ":" 92 ":" 93 ":" 94 ":" 95 ":" 96 ":" 97 ":" 98 ":" 99 ":" 100 ":" 101 ":" 102 ":" 103 ":" 104 ":" 105 ":" 106 ":" 107 ":" 108 ":" 109 ":" 110 ":" 111 ":" 112 ":" 113 ":" 114 ":" 115 ":" 116 ":" 117 ":" 118 ":" 119 ":" 120 ":" 121 ":" 122 ":" 123 ":" 124 ":" 125 ":" 126 ":" 127 ":" 128 ":" 129 ":" 130 ":" 131 ":" 132 ":" 133 ":" 134 ":" 135 ":" 136 ":" 137 ":" 138 ":" 139 ":" 140 ":" 141 ":" 142 ":" 143 ":" 144 ":" 145 ":" 146 ":" 147 ":" 148 ":" 149 ":" 150 ":" 151 ":" 152 ":" 153 ":" 154 ":" 155 ":" 156 ":" 157 ":" 158 ":" 159 ":" 160 ":" 161 ":" 162 ":" 163 ":" 164 ":" 165 ":" 166 ":" 167 ":" 168 ":" 169 ":" 170 ":" 171 ":" 172 ":" 173 ":" 174 ":" 175 ":" 176 ":" 177 ":" 178 ":" 179 ":" 180 ":" 181 ":" 182 ":" 183 ":" 184 ":" 185 ":" 186 ":" 187 ":" 188 ":" 189 ":" 190 ":" 191 ":" 192 ":" 193 ":" 194 ":" 195 ":" 196 ":" 197 ":" 198 ":" 199 ":" 200 ":" 201 ":" 202 ":" 203 ":" 204 ":" 205 ":" 206 ":" 207 ":" 208 ":" 209 ":" 210 ":" 211 ":" 212 ":" 213 ":" 214 ":" 215 ":" 216 ":" 217 ":" 218 ":" 219 ":" 220 ":" 221 ":" 222 ":" 223 ":" 224 ":" 225 ":" 226 ":" 227 ":" 228 ":" 229 ":" 230 ":" 231 ":" 232 ":" 233 ":" 234 ":" 235 ":" 236 ":" 237 ":" 238 ":" 239 ":" 240 ":" 241 ":" 242 ":" 243 ":" 244 ":" 245 ":" 246 ":" 247 ":" 248 ":" 249 ":" 250 ":" 251 ":" 252 ":" 253 ":" 254 ":" 255 ":" ;
VAL_ 645 WDFL_CHA 0 "00b:Standstill" 1 "01b:Drive Wheel Front Direction" 2 "10b:Drive Wheel Rear Direction" 3 "11b:Unavailable" ;
VAL_ 645 WDFR_CHA 0 "00b:Standstill" 1 "01b:Drive Wheel Front Direction" 2 "10b:Drive Wheel Rear Direction" 3 "11b:Unavailable" ;
VAL_ 645 WDRL_CHA 0 "00b:Standstill" 1 "01b:Non Drive Wheel Front Direction" 2 "10b:Non Drive Wheel Rear Direction" 3 "11b:Unavailable" ;
VAL_ 645 WDRR_CHA 0 "00b:Standstill" 1 "01b:Non Drive Wheel Front Direction" 2 "10b:Non Drive Wheel Rear Direction" 3 "11b:Unavailable" ;
VAL_ 645 MSGCOUNT_RW_CHA 0 ":" 1 ":" 2 ":" 3 ":" 4 ":" 5 ":" 6 ":" 7 ":" 8 ":" 9 ":" 10 ":" 11 ":" 12 ":" 13 ":" 14 ":" 15 ":" 16 ":" 17 ":" 18 ":" 19 ":" 20 ":" 21 ":" 22 ":" 23 ":" 24 ":" 25 ":" 26 ":" 27 ":" 28 ":" 29 ":" 30 ":" 31 ":" 32 ":" 33 ":" 34 ":" 35 ":" 36 ":" 37 ":" 38 ":" 39 ":" 40 ":" 41 ":" 42 ":" 43 ":" 44 ":" 45 ":" 46 ":" 47 ":" 48 ":" 49 ":" 50 ":" 51 ":" 52 ":" 53 ":" 54 ":" 55 ":" 56 ":" 57 ":" 58 ":" 59 ":" 60 ":" 61 ":" 62 ":" 63 ":" 64 ":" 65 ":" 66 ":" 67 ":" 68 ":" 69 ":" 70 ":" 71 ":" 72 ":" 73 ":" 74 ":" 75 ":" 76 ":" 77 ":" 78 ":" 79 ":" 80 ":" 81 ":" 82 ":" 83 ":" 84 ":" 85 ":" 86 ":" 87 ":" 88 ":" 89 ":" 90 ":" 91 ":" 92 ":" 93 ":" 94 ":" 95 ":" 96 ":" 97 ":" 98 ":" 99 ":" 100 ":" 101 ":" 102 ":" 103 ":" 104 ":" 105 ":" 106 ":" 107 ":" 108 ":" 109 ":" 110 ":" 111 ":" 112 ":" 113 ":" 114 ":" 115 ":" 116 ":" 117 ":" 118 ":" 119 ":" 120 ":" 121 ":" 122 ":" 123 ":" 124 ":" 125 ":" 126 ":" 127 ":" 128 ":" 129 ":" 130 ":" 131 ":" 132 ":" 133 ":" 134 ":" 135 ":" 136 ":" 137 ":" 138 ":" 139 ":" 140 ":" 141 ":" 142 ":" 143 ":" 144 ":" 145 ":" 146 ":" 147 ":" 148 ":" 149 ":" 150 ":" 151 ":" 152 ":" 153 ":" 154 ":" 155 ":" 156 ":" 157 ":" 158 ":" 159 ":" 160 ":" 161 ":" 162 ":" 163 ":" 164 ":" 165 ":" 166 ":" 167 ":" 168 ":" 169 ":" 170 ":" 171 ":" 172 ":" 173 ":" 174 ":" 175 ":" 176 ":" 177 ":" 178 ":" 179 ":" 180 ":" 181 ":" 182 ":" 183 ":" 184 ":" 185 ":" 186 ":" 187 ":" 188 ":" 189 ":" 190 ":" 191 ":" 192 ":" 193 ":" 194 ":" 195 ":" 196 ":" 197 ":" 198 ":" 199 ":" 200 ":" 201 ":" 202 ":" 203 ":" 204 ":" 205 ":" 206 ":" 207 ":" 208 ":" 209 ":" 210 ":" 211 ":" 212 ":" 213 ":" 214 ":" 215 ":" 216 ":" 217 ":" 218 ":" 219 ":" 220 ":" 221 ":" 222 ":" 223 ":" 224 ":" 225 ":" 226 ":" 227 ":" 228 ":" 229 ":" 230 ":" 231 ":" 232 ":" 233 ":" 234 ":" 235 ":" 236 ":" 237 ":" 238 ":" 239 ":" 240 ":" 241 ":" 242 ":" 243 ":" 244 ":" 245 ":" 246 ":" 247 ":" 248 ":" 249 ":" 250 ":" 251 ":" 252 ":" 253 ":" 254 ":" 255 ":" ;
VAL_ 645 CHKSUMFR_RW_CHA 0 ":" 1 ":" 2 ":" 3 ":" 4 ":" 5 ":" 6 ":" 7 ":" 8 ":" 9 ":" 10 ":" 11 ":" 12 ":" 13 ":" 14 ":" 15 ":" 16 ":" 17 ":" 18 ":" 19 ":" 20 ":" 21 ":" 22 ":" 23 ":" 24 ":" 25 ":" 26 ":" 27 ":" 28 ":" 29 ":" 30 ":" 31 ":" 32 ":" 33 ":" 34 ":" 35 ":" 36 ":" 37 ":" 38 ":" 39 ":" 40 ":" 41 ":" 42 ":" 43 ":" 44 ":" 45 ":" 46 ":" 47 ":" 48 ":" 49 ":" 50 ":" 51 ":" 52 ":" 53 ":" 54 ":" 55 ":" 56 ":" 57 ":" 58 ":" 59 ":" 60 ":" 61 ":" 62 ":" 63 ":" 64 ":" 65 ":" 66 ":" 67 ":" 68 ":" 69 ":" 70 ":" 71 ":" 72 ":" 73 ":" 74 ":" 75 ":" 76 ":" 77 ":" 78 ":" 79 ":" 80 ":" 81 ":" 82 ":" 83 ":" 84 ":" 85 ":" 86 ":" 87 ":" 88 ":" 89 ":" 90 ":" 91 ":" 92 ":" 93 ":" 94 ":" 95 ":" 96 ":" 97 ":" 98 ":" 99 ":" 100 ":" 101 ":" 102 ":" 103 ":" 104 ":" 105 ":" 106 ":" 107 ":" 108 ":" 109 ":" 110 ":" 111 ":" 112 ":" 113 ":" 114 ":" 115 ":" 116 ":" 117 ":" 118 ":" 119 ":" 120 ":" 121 ":" 122 ":" 123 ":" 124 ":" 125 ":" 126 ":" 127 ":" 128 ":" 129 ":" 130 ":" 131 ":" 132 ":" 133 ":" 134 ":" 135 ":" 136 ":" 137 ":" 138 ":" 139 ":" 140 ":" 141 ":" 142 ":" 143 ":" 144 ":" 145 ":" 146 ":" 147 ":" 148 ":" 149 ":" 150 ":" 151 ":" 152 ":" 153 ":" 154 ":" 155 ":" 156 ":" 157 ":" 158 ":" 159 ":" 160 ":" 161 ":" 162 ":" 163 ":" 164 ":" 165 ":" 166 ":" 167 ":" 168 ":" 169 ":" 170 ":" 171 ":" 172 ":" 173 ":" 174 ":" 175 ":" 176 ":" 177 ":" 178 ":" 179 ":" 180 ":" 181 ":" 182 ":" 183 ":" 184 ":" 185 ":" 186 ":" 187 ":" 188 ":" 189 ":" 190 ":" 191 ":" 192 ":" 193 ":" 194 ":" 195 ":" 196 ":" 197 ":" 198 ":" 199 ":" 200 ":" 201 ":" 202 ":" 203 ":" 204 ":" 205 ":" 206 ":" 207 ":" 208 ":" 209 ":" 210 ":" 211 ":" 212 ":" 213 ":" 214 ":" 215 ":" 216 ":" 217 ":" 218 ":" 219 ":" 220 ":" 221 ":" 222 ":" 223 ":" 224 ":" 225 ":" 226 ":" 227 ":" 228 ":" 229 ":" 230 ":" 231 ":" 232 ":" 233 ":" 234 ":" 235 ":" 236 ":" 237 ":" 238 ":" 239 ":" 240 ":" 241 ":" 242 ":" 243 ":" 244 ":" 245 ":" 246 ":" 247 ":" 248 ":" 249 ":" 250 ":" 251 ":" 252 ":" 253 ":" 254 ":" 255 ":" ;
VAL_ 646 WSPFL 0 ":" 1 ":" 2 ":" 3 ":" 4 ":" 5 ":" 6 ":" 7 ":" 8 ":" 9 ":" 10 ":" 11 ":" 12 ":" 13 ":" 14 ":" 15 ":" 16 ":" 17 ":" 18 ":" 19 ":" 20 ":" 21 ":" 22 ":" 23 ":" 24 ":" 25 ":" 26 ":" 27 ":" 28 ":" 29 ":" 30 ":" 31 ":" 32 ":" 33 ":" 34 ":" 35 ":" 36 ":" 37 ":" 38 ":" 39 ":" 40 ":" 41 ":" 42 ":" 43 ":" 44 ":" 45 ":" 46 ":" 47 ":" 48 ":" 49 ":" 50 ":" 51 ":" 52 ":" 53 ":" 54 ":" 55 ":" 56 ":" 57 ":" 58 ":" 59 ":" 60 ":" 61 ":" 62 ":" 63 ":" ;
VAL_ 646 WSPFR 0 ":" 1 ":" 2 ":" 3 ":" 4 ":" 5 ":" 6 ":" 7 ":" 8 ":" 9 ":" 10 ":" 11 ":" 12 ":" 13 ":" 14 ":" 15 ":" 16 ":" 17 ":" 18 ":" 19 ":" 20 ":" 21 ":" 22 ":" 23 ":" 24 ":" 25 ":" 26 ":" 27 ":" 28 ":" 29 ":" 30 ":" 31 ":" 32 ":" 33 ":" 34 ":" 35 ":" 36 ":" 37 ":" 38 ":" 39 ":" 40 ":" 41 ":" 42 ":" 43 ":" 44 ":" 45 ":" 46 ":" 47 ":" 48 ":" 49 ":" 50 ":" 51 ":" 52 ":" 53 ":" 54 ":" 55 ":" 56 ":" 57 ":" 58 ":" 59 ":" 60 ":" 61 ":" 62 ":" 63 ":" 64 ":" 65 ":" 66 ":" 67 ":" 68 ":" 69 ":" 70 ":" 71 ":" 72 ":" 73 ":" 74 ":" 75 ":" 76 ":" 77 ":" 78 ":" 79 ":" 80 ":" 81 ":" 82 ":" 83 ":" 84 ":" 85 ":" 86 ":" 87 ":" 88 ":" 89 ":" 90 ":" 91 ":" 92 ":" 93 ":" 94 ":" 95 ":" 96 ":" 97 ":" 98 ":" 99 ":" 100 ":" 101 ":" 102 ":" 103 ":" 104 ":" 105 ":" 106 ":" 107 ":" 108 ":" 109 ":" 110 ":" 111 ":" 112 ":" 113 ":" 114 ":" 115 ":" 116 ":" 117 ":" 118 ":" 119 ":" 120 ":" 121 ":" 122 ":" 123 ":" 124 ":" 125 ":" 126 ":" 127 ":" ;
VAL_ 646 WSPRL 0 ":" 1 ":" 2 ":" 3 ":" 4 ":" 5 ":" 6 ":" 7 ":" 8 ":" 9 ":" 10 ":" 11 ":" 12 ":" 13 ":" 14 ":" 15 ":" 16 ":" 17 ":" 18 ":" 19 ":" 20 ":" 21 ":" 22 ":" 23 ":" 24 ":" 25 ":" 26 ":" 27 ":" 28 ":" 29 ":" 30 ":" 31 ":" 32 ":" 33 ":" 34 ":" 35 ":" 36 ":" 37 ":" 38 ":" 39 ":" 40 ":" 41 ":" 42 ":" 43 ":" 44 ":" 45 ":" 46 ":" 47 ":" 48 ":" 49 ":" 50 ":" 51 ":" 52 ":" 53 ":" 54 ":" 55 ":" 56 ":" 57 ":" 58 ":" 59 ":" 60 ":" 61 ":" 62 ":" 63 ":" 64 ":" 65 ":" 66 ":" 67 ":" 68 ":" 69 ":" 70 ":" 71 ":" 72 ":" 73 ":" 74 ":" 75 ":" 76 ":" 77 ":" 78 ":" 79 ":" 80 ":" 81 ":" 82 ":" 83 ":" 84 ":" 85 ":" 86 ":" 87 ":" 88 ":" 89 ":" 90 ":" 91 ":" 92 ":" 93 ":" 94 ":" 95 ":" 96 ":" 97 ":" 98 ":" 99 ":" 100 ":" 101 ":" 102 ":" 103 ":" 104 ":" 105 ":" 106 ":" 107 ":" 108 ":" 109 ":" 110 ":" 111 ":" 112 ":" 113 ":" 114 ":" 115 ":" 116 ":" 117 ":" 118 ":" 119 ":" 120 ":" 121 ":" 122 ":" 123 ":" 124 ":" 125 ":" 126 ":" 127 ":" ;
VAL_ 646 WSPRR 0 ":" 1 ":" ;
VAL_ 658 BSTERIRStro 0 ":" 1 ":" 2 ":" 3 ":" 4 ":" 5 ":" 6 ":" 7 ":" 8 ":" 9 ":" 10 ":" 11 ":" 12 ":" 13 ":" 14 ":" 15 ":" 16 ":" 17 ":" 18 ":" 19 ":" 20 ":" 21 ":" 22 ":" 23 ":" 24 ":" 25 ":" 26 ":" 27 ":" 28 ":" 29 ":" 30 ":" 31 ":" 32 ":" 33 ":" 34 ":" 35 ":" 36 ":" 37 ":" 38 ":" 39 ":" 40 ":" 41 ":" 42 ":" 43 ":" 44 ":" 45 ":" 46 ":" 47 ":" 48 ":" 49 ":" 50 ":" 51 ":" 52 ":" 53 ":" 54 ":" 55 ":" 56 ":" 57 ":" 58 ":" 59 ":" 60 ":" 61 ":" 62 ":" 63 ":" 64 ":" 65 ":" 66 ":" 67 ":" 68 ":" 69 ":" 70 ":" 71 ":" 72 ":" 73 ":" 74 ":" 75 ":" 76 ":" 77 ":" 78 ":" 79 ":" 80 ":" 81 ":" 82 ":" 83 ":" 84 ":" 85 ":" 86 ":" 87 ":" 88 ":" 89 ":" 90 ":" 91 ":" 92 ":" 93 ":" 94 ":" 95 ":" 96 ":" 97 ":" 98 ":" 99 ":" 100 ":" 101 ":" 102 ":" 103 ":" 104 ":" 105 ":" 106 ":" 107 ":" 108 ":" 109 ":" 110 ":" 111 ":" 112 ":" 113 ":" 114 ":" 115 ":" 116 ":" 117 ":" 118 ":" 119 ":" 120 ":" 121 ":" 122 ":" 123 ":" 124 ":" 125 ":" 126 ":" 127 ":" 128 ":" 129 ":" 130 ":" 131 ":" 132 ":" 133 ":" 134 ":" 135 ":" 136 ":" 137 ":" 138 ":" 139 ":" 140 ":" 141 ":" 142 ":" 143 ":" 144 ":" 145 ":" 146 ":" 147 ":" 148 ":" 149 ":" 150 ":" 151 ":" 152 ":" 153 ":" 154 ":" 155 ":" 156 ":" 157 ":" 158 ":" 159 ":" 160 ":" 161 ":" 162 ":" 163 ":" 164 ":" 165 ":" 166 ":" 167 ":" 168 ":" 169 ":" 170 ":" 171 ":" 172 ":" 173 ":" 174 ":" 175 ":" 176 ":" 177 ":" 178 ":" 179 ":" 180 ":" 181 ":" 182 ":" 183 ":" 184 ":" 185 ":" 186 ":" 187 ":" 188 ":" 189 ":" 190 ":" 191 ":" 192 ":" 193 ":" 194 ":" 195 ":" 196 ":" 197 ":" 198 ":" 199 ":" 200 ":" 201 ":" 202 ":" 203 ":" 204 ":" 205 ":" 206 ":" 207 ":" 208 ":" 209 ":" 210 ":" 211 ":" 212 ":" 213 ":" 214 ":" 215 ":" 216 ":" 217 ":" 218 ":" 219 ":" 220 ":" 221 ":" 222 ":" 223 ":" 224 ":" 225 ":" 226 ":" 227 ":" 228 ":" 229 ":" 230 ":" 231 ":" 232 ":" 233 ":" 234 ":" 235 ":" 236 ":" 237 ":" 238 ":" 239 ":" 240 ":" 241 ":" 242 ":" 243 ":" 244 ":" 245 ":" 246 ":" 247 ":" 248 ":" 249 ":" 250 ":" 251 ":" 252 ":" 253 ":" 254 ":" 255 ":" ;
VAL_ 658 BSTERPRE 0 ":" 1 ":" 2 ":" 3 ":" 4 ":" 5 ":" 6 ":" 7 ":" 8 ":" 9 ":" 10 ":" 11 ":" 12 ":" 13 ":" 14 ":" 15 ":" ;
VAL_ 658 PSS_02 0 ":" 1 ":" 2 ":" 3 ":" 4 ":" 5 ":" 6 ":" 7 ":" 8 ":" 9 ":" 10 ":" 11 ":" 12 ":" 13 ":" 14 ":" 15 ":" 16 ":" 17 ":" 18 ":" 19 ":" 20 ":" 21 ":" 22 ":" 23 ":" 24 ":" 25 ":" 26 ":" 27 ":" 28 ":" 29 ":" 30 ":" 31 ":" 32 ":" 33 ":" 34 ":" 35 ":" 36 ":" 37 ":" 38 ":" 39 ":" 40 ":" 41 ":" 42 ":" 43 ":" 44 ":" 45 ":" 46 ":" 47 ":" 48 ":" 49 ":" 50 ":" 51 ":" 52 ":" 53 ":" 54 ":" 55 ":" 56 ":" 57 ":" 58 ":" 59 ":" 60 ":" 61 ":" 62 ":" 63 ":" 64 ":" 65 ":" 66 ":" 67 ":" 68 ":" 69 ":" 70 ":" 71 ":" 72 ":" 73 ":" 74 ":" 75 ":" 76 ":" 77 ":" 78 ":" 79 ":" 80 ":" 81 ":" 82 ":" 83 ":" 84 ":" 85 ":" 86 ":" 87 ":" 88 ":" 89 ":" 90 ":" 91 ":" 92 ":" 93 ":" 94 ":" 95 ":" 96 ":" 97 ":" 98 ":" 99 ":" 100 ":" 101 ":" 102 ":" 103 ":" 104 ":" 105 ":" 106 ":" 107 ":" 108 ":" 109 ":" 110 ":" 111 ":" 112 ":" 113 ":" 114 ":" 115 ":" 116 ":" 117 ":" 118 ":" 119 ":" 120 ":" 121 ":" 122 ":" 123 ":" 124 ":" 125 ":" 126 ":" 127 ":" 128 ":" 129 ":" 130 ":" 131 ":" 132 ":" 133 ":" 134 ":" 135 ":" 136 ":" 137 ":" 138 ":" 139 ":" 140 ":" 141 ":" 142 ":" 143 ":" 144 ":" 145 ":" 146 ":" 147 ":" 148 ":" 149 ":" 150 ":" 151 ":" 152 ":" 153 ":" 154 ":" 155 ":" 156 ":" 157 ":" 158 ":" 159 ":" 160 ":" 161 ":" 162 ":" 163 ":" 164 ":" 165 ":" 166 ":" 167 ":" 168 ":" 169 ":" 170 ":" 171 ":" 172 ":" 173 ":" 174 ":" 175 ":" 176 ":" 177 ":" 178 ":" 179 ":" 180 ":" 181 ":" 182 ":" 183 ":" 184 ":" 185 ":" 186 ":" 187 ":" 188 ":" 189 ":" 190 ":" 191 ":" 192 ":" 193 ":" 194 ":" 195 ":" 196 ":" 197 ":" 198 ":" 199 ":" 200 ":" 201 ":" 202 ":" 203 ":" 204 ":" 205 ":" 206 ":" 207 ":" 208 ":" 209 ":" 210 ":" 211 ":" 212 ":" 213 ":" 214 ":" 215 ":" 216 ":" 217 ":" 218 ":" 219 ":" 220 ":" 221 ":" 222 ":" 223 ":" 224 ":" 225 ":" 226 ":" 227 ":" 228 ":" 229 ":" 230 ":" 231 ":" 232 ":" 233 ":" 234 ":" 235 ":" 236 ":" 237 ":" 238 ":" 239 ":" 240 ":" 241 ":" 242 ":" 243 ":" 244 ":" 245 ":" 246 ":" 247 ":" 248 ":" 249 ":" 250 ":" 251 ":" 252 ":" 253 ":" 254 ":" 255 ":" ;
VAL_ 658 CHCKSUM_VD 0 ":" 1 ":" 2 ":" 3 ":" 4 ":" 5 ":" 6 ":" 7 ":" 8 ":" 9 ":" 10 ":" 11 ":" 12 ":" 13 ":" 14 ":" 15 ":" ;
VAL_ 658 MVP_COUNT 0 ":" 1 ":" 2 ":" 3 ":" ;
VAL_ 852 VSO_CHA_BGD 0 ":" 1 ":" 2 ":" 3 ":" 4 ":" 5 ":" 6 ":" 7 ":" 8 ":" 9 ":" 10 ":" 11 ":" 12 ":" 13 ":" 14 ":" 15 ":" 16 ":" 17 ":" 18 ":" 19 ":" 20 ":" 21 ":" 22 ":" 23 ":" 24 ":" 25 ":" 26 ":" 27 ":" 28 ":" 29 ":" 30 ":" 31 ":" 32 ":" 33 ":" 34 ":" 35 ":" 36 ":" 37 ":" 38 ":" 39 ":" 40 ":" 41 ":" 42 ":" 43 ":" 44 ":" 45 ":" 46 ":" 47 ":" 48 ":" 49 ":" 50 ":" 51 ":" 52 ":" 53 ":" 54 ":" 55 ":" 56 ":" 57 ":" 58 ":" 59 ":" 60 ":" 61 ":" 62 ":" 63 ":" 64 ":" 65 ":" 66 ":" 67 ":" 68 ":" 69 ":" 70 ":" 71 ":" 72 ":" 73 ":" 74 ":" 75 ":" 76 ":" 77 ":" 78 ":" 79 ":" 80 ":" 81 ":" 82 ":" 83 ":" 84 ":" 85 ":" 86 ":" 87 ":" 88 ":" 89 ":" 90 ":" 91 ":" 92 ":" 93 ":" 94 ":" 95 ":" 96 ":" 97 ":" 98 ":" 99 ":" 100 ":" 101 ":" 102 ":" 103 ":" 104 ":" 105 ":" 106 ":" 107 ":" 108 ":" 109 ":" 110 ":" 111 ":" 112 ":" 113 ":" 114 ":" 115 ":" 116 ":" 117 ":" 118 ":" 119 ":" 120 ":" 121 ":" 122 ":" 123 ":" 124 ":" 125 ":" 126 ":" 127 ":" 128 ":" 129 ":" 130 ":" 131 ":" 132 ":" 133 ":" 134 ":" 135 ":" 136 ":" 137 ":" 138 ":" 139 ":" 140 ":" 141 ":" 142 ":" 143 ":" 144 ":" 145 ":" 146 ":" 147 ":" 148 ":" 149 ":" 150 ":" 151 ":" 152 ":" 153 ":" 154 ":" 155 ":" 156 ":" 157 ":" 158 ":" 159 ":" 160 ":" 161 ":" 162 ":" 163 ":" 164 ":" 165 ":" 166 ":" 167 ":" 168 ":" 169 ":" 170 ":" 171 ":" 172 ":" 173 ":" 174 ":" 175 ":" 176 ":" 177 ":" 178 ":" 179 ":" 180 ":" 181 ":" 182 ":" 183 ":" 184 ":" 185 ":" 186 ":" 187 ":" 188 ":" 189 ":" 190 ":" 191 ":" 192 ":" 193 ":" 194 ":" 195 ":" 196 ":" 197 ":" 198 ":" 199 ":" 200 ":" 201 ":" 202 ":" 203 ":" 204 ":" 205 ":" 206 ":" 207 ":" 208 ":" 209 ":" 210 ":" 211 ":" 212 ":" 213 ":" 214 ":" 215 ":" 216 ":" 217 ":" 218 ":" 219 ":" 220 ":" 221 ":" 222 ":" 223 ":" 224 ":" 225 ":" 226 ":" 227 ":" 228 ":" 229 ":" 230 ":" 231 ":" 232 ":" 233 ":" 234 ":" 235 ":" 236 ":" 237 ":" 238 ":" 239 ":" 240 ":" 241 ":" 242 ":" 243 ":" 244 ":" 245 ":" 246 ":" 247 ":" 248 ":" 249 ":" 250 ":" 251 ":" 252 ":" 253 ":" 254 ":" 255 ":" ;
VAL_ 852 WBF_TORQUE_CHA 0 ":" 1 ":" 2 ":" 3 ":" 4 ":" 5 ":" 6 ":" 7 ":" 8 ":" 9 ":" 10 ":" 11 ":" 12 ":" 13 ":" 14 ":" 15 ":" 16 ":" 17 ":" 18 ":" 19 ":" 20 ":" 21 ":" 22 ":" 23 ":" 24 ":" 25 ":" 26 ":" 27 ":" 28 ":" 29 ":" 30 ":" 31 ":" 32 ":" 33 ":" 34 ":" 35 ":" 36 ":" 37 ":" 38 ":" 39 ":" 40 ":" 41 ":" 42 ":" 43 ":" 44 ":" 45 ":" 46 ":" 47 ":" 48 ":" 49 ":" 50 ":" 51 ":" 52 ":" 53 ":" 54 ":" 55 ":" 56 ":" 57 ":" 58 ":" 59 ":" 60 ":" 61 ":" 62 ":" 63 ":" 64 ":" 65 ":" 66 ":" 67 ":" 68 ":" 69 ":" 70 ":" 71 ":" 72 ":" 73 ":" 74 ":" 75 ":" 76 ":" 77 ":" 78 ":" 79 ":" 80 ":" 81 ":" 82 ":" 83 ":" 84 ":" 85 ":" 86 ":" 87 ":" 88 ":" 89 ":" 90 ":" 91 ":" 92 ":" 93 ":" 94 ":" 95 ":" 96 ":" 97 ":" 98 ":" 99 ":" 100 ":" 101 ":" 102 ":" 103 ":" 104 ":" 105 ":" 106 ":" 107 ":" 108 ":" 109 ":" 110 ":" 111 ":" 112 ":" 113 ":" 114 ":" 115 ":" 116 ":" 117 ":" 118 ":" 119 ":" 120 ":" 121 ":" 122 ":" 123 ":" 124 ":" 125 ":" 126 ":" 127 ":" 128 ":" 129 ":" 130 ":" 131 ":" 132 ":" 133 ":" 134 ":" 135 ":" 136 ":" 137 ":" 138 ":" 139 ":" 140 ":" 141 ":" 142 ":" 143 ":" 144 ":" 145 ":" 146 ":" 147 ":" 148 ":" 149 ":" 150 ":" 151 ":" 152 ":" 153 ":" 154 ":" 155 ":" 156 ":" 157 ":" 158 ":" 159 ":" 160 ":" 161 ":" 162 ":" 163 ":" 164 ":" 165 ":" 166 ":" 167 ":" 168 ":" 169 ":" 170 ":" 171 ":" 172 ":" 173 ":" 174 ":" 175 ":" 176 ":" 177 ":" 178 ":" 179 ":" 180 ":" 181 ":" 182 ":" 183 ":" 184 ":" 185 ":" 186 ":" 187 ":" 188 ":" 189 ":" 190 ":" 191 ":" 192 ":" 193 ":" 194 ":" 195 ":" 196 ":" 197 ":" 198 ":" 199 ":" 200 ":" 201 ":" 202 ":" 203 ":" 204 ":" 205 ":" 206 ":" 207 ":" 208 ":" 209 ":" 210 ":" 211 ":" 212 ":" 213 ":" 214 ":" 215 ":" 216 ":" 217 ":" 218 ":" 219 ":" 220 ":" 221 ":" 222 ":" 223 ":" 224 ":" 225 ":" 226 ":" 227 ":" 228 ":" 229 ":" 230 ":" 231 ":" 232 ":" 233 ":" 234 ":" 235 ":" 236 ":" 237 ":" 238 ":" 239 ":" 240 ":" 241 ":" 242 ":" 243 ":" 244 ":" 245 ":" 246 ":" 247 ":" 248 ":" 249 ":" 250 ":" 251 ":" 252 ":" 253 ":" 254 ":" 255 ":" ;
VAL_ 852 EBDACT_CHA 0 "0b:EBV not regulating" 1 "1b:EBV regulating" ;
VAL_ 852 MSGCNTR_CHA 0 ":" 1 ":" 2 ":" 3 ":" ;
VAL_ 852 ABSFAIL_CHA 0 "0b:ABS OK" 1 "1b:ABS malfunction" ;
VAL_ 852 ABSACT_CHA 0 "0b:ABS not in regulation" 1 "1b:ABS in regulation" ;
VAL_ 852 STPLMSW_CHA 0 "00b:brake not active" 1 "01b:brake active" 2 "10b:Not used" 3 "11b:invalid" ;
VAL_ 576 EPB_STAT 0 "000b:Unknown state" 1 "001b:Applied" 2 "010b:Released" 3 "011b:Applying" 4 "100b:Releasing" 5 "101b:System calibrating" 6 "110b:Specific status" 7 "111b:EPB lamps check" ;
VAL_ 576 EPB_FAIL 0 "0b:" 1 "1b:Abnormal" ;
VAL_ 576 DPB_STAT 0 "00b:OFF" 1 "01b:DPB operation by IBC" 2 "10b:DPB operation by electro-caliper" 3 "11b:Not Used" ;
VAL_ 576 EPB_SW_STAT 0 "00b:Netrual" 1 "01b:Apply" 2 "10b:invalid" 3 "11b:reserved" ;
VAL_ 576 EPB_ENBL 0 "0b:EPB Enable" 1 "1b:EPB not Enable" ;
VAL_ 576 ALIVECOUNTER 0 ":" 1 ":" 2 ":" 3 ":" 4 ":" 5 ":" 6 ":" 7 ":" 8 ":" 9 ":" 10 ":" 11 ":" 12 ":" 13 ":" 14 ":" 15 ":" ;
VAL_ 576 CHKSUM_EPB 0 ":" 1 ":" 2 ":" 3 ":" 4 ":" 5 ":" 6 ":" 7 ":" 8 ":" 9 ":" 10 ":" 11 ":" 12 ":" 13 ":" 14 ":" 15 ":" 16 ":" 17 ":" 18 ":" 19 ":" 20 ":" 21 ":" 22 ":" 23 ":" 24 ":" 25 ":" 26 ":" 27 ":" 28 ":" 29 ":" 30 ":" 31 ":" 32 ":" 33 ":" 34 ":" 35 ":" 36 ":" 37 ":" 38 ":" 39 ":" 40 ":" 41 ":" 42 ":" 43 ":" 44 ":" 45 ":" 46 ":" 47 ":" 48 ":" 49 ":" 50 ":" 51 ":" 52 ":" 53 ":" 54 ":" 55 ":" 56 ":" 57 ":" 58 ":" 59 ":" 60 ":" 61 ":" 62 ":" 63 ":" 64 ":" 65 ":" 66 ":" 67 ":" 68 ":" 69 ":" 70 ":" 71 ":" 72 ":" 73 ":" 74 ":" 75 ":" 76 ":" 77 ":" 78 ":" 79 ":" 80 ":" 81 ":" 82 ":" 83 ":" 84 ":" 85 ":" 86 ":" 87 ":" 88 ":" 89 ":" 90 ":" 91 ":" 92 ":" 93 ":" 94 ":" 95 ":" 96 ":" 97 ":" 98 ":" 99 ":" 100 ":" 101 ":" 102 ":" 103 ":" 104 ":" 105 ":" 106 ":" 107 ":" 108 ":" 109 ":" 110 ":" 111 ":" 112 ":" 113 ":" 114 ":" 115 ":" 116 ":" 117 ":" 118 ":" 119 ":" 120 ":" 121 ":" 122 ":" 123 ":" 124 ":" 125 ":" 126 ":" 127 ":" 128 ":" 129 ":" 130 ":" 131 ":" 132 ":" 133 ":" 134 ":" 135 ":" 136 ":" 137 ":" 138 ":" 139 ":" 140 ":" 141 ":" 142 ":" 143 ":" 144 ":" 145 ":" 146 ":" 147 ":" 148 ":" 149 ":" 150 ":" 151 ":" 152 ":" 153 ":" 154 ":" 155 ":" 156 ":" 157 ":" 158 ":" 159 ":" 160 ":" 161 ":" 162 ":" 163 ":" 164 ":" 165 ":" 166 ":" 167 ":" 168 ":" 169 ":" 170 ":" 171 ":" 172 ":" 173 ":" 174 ":" 175 ":" 176 ":" 177 ":" 178 ":" 179 ":" 180 ":" 181 ":" 182 ":" 183 ":" 184 ":" 185 ":" 186 ":" 187 ":" 188 ":" 189 ":" 190 ":" 191 ":" 192 ":" 193 ":" 194 ":" 195 ":" 196 ":" 197 ":" 198 ":" 199 ":" 200 ":" 201 ":" 202 ":" 203 ":" 204 ":" 205 ":" 206 ":" 207 ":" 208 ":" 209 ":" 210 ":" 211 ":" 212 ":" 213 ":" 214 ":" 215 ":" 216 ":" 217 ":" 218 ":" 219 ":" 220 ":" 221 ":" 222 ":" 223 ":" 224 ":" 225 ":" 226 ":" 227 ":" 228 ":" 229 ":" 230 ":" 231 ":" 232 ":" 233 ":" 234 ":" 235 ":" 236 ":" 237 ":" 238 ":" 239 ":" 240 ":" 241 ":" 242 ":" 243 ":" 244 ":" 245 ":" 246 ":" 247 ":" 248 ":" 249 ":" 250 ":" 251 ":" 252 ":" 253 ":" 254 ":" 255 ":" ;
VAL_ 1418 AVH_OFFSW 0 "0b:AVH not available" 1 "1b:AVH available" ;
VAL_ 1418 AVH_ACT 0 "0b:AVH not operation" 1 "1b:AVH operation" ;
VAL_ 1418 AVH_FAIL 0 "0b:" 1 "1b:Abnormal" ;
VAL_ 1418 CHKSUM_IBC 0 ":" 1 ":" 2 ":" 3 ":" 4 ":" 5 ":" 6 ":" 7 ":" 8 ":" 9 ":" 10 ":" 11 ":" 12 ":" 13 ":" 14 ":" 15 ":" 16 ":" 17 ":" 18 ":" 19 ":" 20 ":" 21 ":" 22 ":" 23 ":" 24 ":" 25 ":" 26 ":" 27 ":" 28 ":" 29 ":" 30 ":" 31 ":" 32 ":" 33 ":" 34 ":" 35 ":" 36 ":" 37 ":" 38 ":" 39 ":" 40 ":" 41 ":" 42 ":" 43 ":" 44 ":" 45 ":" 46 ":" 47 ":" 48 ":" 49 ":" 50 ":" 51 ":" 52 ":" 53 ":" 54 ":" 55 ":" 56 ":" 57 ":" 58 ":" 59 ":" 60 ":" 61 ":" 62 ":" 63 ":" 64 ":" 65 ":" 66 ":" 67 ":" 68 ":" 69 ":" 70 ":" 71 ":" 72 ":" 73 ":" 74 ":" 75 ":" 76 ":" 77 ":" 78 ":" 79 ":" 80 ":" 81 ":" 82 ":" 83 ":" 84 ":" 85 ":" 86 ":" 87 ":" 88 ":" 89 ":" 90 ":" 91 ":" 92 ":" 93 ":" 94 ":" 95 ":" 96 ":" 97 ":" 98 ":" 99 ":" 100 ":" 101 ":" 102 ":" 103 ":" 104 ":" 105 ":" 106 ":" 107 ":" 108 ":" 109 ":" 110 ":" 111 ":" 112 ":" 113 ":" 114 ":" 115 ":" 116 ":" 117 ":" 118 ":" 119 ":" 120 ":" 121 ":" 122 ":" 123 ":" 124 ":" 125 ":" 126 ":" 127 ":" 128 ":" 129 ":" 130 ":" 131 ":" 132 ":" 133 ":" 134 ":" 135 ":" 136 ":" 137 ":" 138 ":" 139 ":" 140 ":" 141 ":" 142 ":" 143 ":" 144 ":" 145 ":" 146 ":" 147 ":" 148 ":" 149 ":" 150 ":" 151 ":" 152 ":" 153 ":" 154 ":" 155 ":" 156 ":" 157 ":" 158 ":" 159 ":" 160 ":" 161 ":" 162 ":" 163 ":" 164 ":" 165 ":" 166 ":" 167 ":" 168 ":" 169 ":" 170 ":" 171 ":" 172 ":" 173 ":" 174 ":" 175 ":" 176 ":" 177 ":" 178 ":" 179 ":" 180 ":" 181 ":" 182 ":" 183 ":" 184 ":" 185 ":" 186 ":" 187 ":" 188 ":" 189 ":" 190 ":" 191 ":" 192 ":" 193 ":" 194 ":" 195 ":" 196 ":" 197 ":" 198 ":" 199 ":" 200 ":" 201 ":" 202 ":" 203 ":" 204 ":" 205 ":" 206 ":" 207 ":" 208 ":" 209 ":" 210 ":" 211 ":" 212 ":" 213 ":" 214 ":" 215 ":" 216 ":" 217 ":" 218 ":" 219 ":" 220 ":" 221 ":" 222 ":" 223 ":" 224 ":" 225 ":" 226 ":" 227 ":" 228 ":" 229 ":" 230 ":" 231 ":" 232 ":" 233 ":" 234 ":" 235 ":" 236 ":" 237 ":" 238 ":" 239 ":" 240 ":" 241 ":" 242 ":" 243 ":" 244 ":" 245 ":" 246 ":" 247 ":" 248 ":" 249 ":" 250 ":" 251 ":" 252 ":" 253 ":" 254 ":" 255 ":" ;
VAL_ 456 AEB_AXTAR 0 ":" 1 ":" 2 ":" 3 ":" 4 ":" 5 ":" 6 ":" 7 ":" 8 ":" 9 ":" 10 ":" 11 ":" 12 ":" 13 ":" 14 ":" 15 ":" 16 ":" 17 ":" 18 ":" 19 ":" 20 ":" 21 ":" 22 ":" 23 ":" 24 ":" 25 ":" 26 ":" 27 ":" 28 ":" 29 ":" 30 ":" 31 ":" 32 ":" 33 ":" 34 ":" 35 ":" 36 ":" 37 ":" 38 ":" 39 ":" 40 ":" 41 ":" 42 ":" 43 ":" 44 ":" 45 ":" 46 ":" 47 ":" 48 ":" 49 ":" 50 ":" 51 ":" 52 ":" 53 ":" 54 ":" 55 ":" 56 ":" 57 ":" 58 ":" 59 ":" 60 ":" 61 ":" 62 ":" 63 ":" 64 ":" 65 ":" 66 ":" 67 ":" 68 ":" 69 ":" 70 ":" 71 ":" 72 ":" 73 ":" 74 ":" 75 ":" 76 ":" 77 ":" 78 ":" 79 ":" 80 ":" 81 ":" 82 ":" 83 ":" 84 ":" 85 ":" 86 ":" 87 ":" 88 ":" 89 ":" 90 ":" 91 ":" 92 ":" 93 ":" 94 ":" 95 ":" 96 ":" 97 ":" 98 ":" 99 ":" 100 ":" 101 ":" 102 ":" 103 ":" 104 ":" 105 ":" 106 ":" 107 ":" 108 ":" 109 ":" 110 ":" 111 ":" 112 ":" 113 ":" 114 ":" 115 ":" 116 ":" 117 ":" 118 ":" 119 ":" 120 ":" 121 ":" 122 ":" 123 ":" 124 ":" 125 ":" 126 ":" 127 ":" 128 ":" 129 ":" 130 ":" 131 ":" 132 ":" 133 ":" 134 ":" 135 ":" 136 ":" 137 ":" 138 ":" 139 ":" 140 ":" 141 ":" 142 ":" 143 ":" 144 ":" 145 ":" 146 ":" 147 ":" 148 ":" 149 ":" 150 ":" 151 ":" 152 ":" 153 ":" 154 ":" 155 ":" 156 ":" 157 ":" 158 ":" 159 ":" 160 ":" 161 ":" 162 ":" 163 ":" 164 ":" 165 ":" 166 ":" 167 ":" 168 ":" 169 ":" 170 ":" 171 ":" 172 ":" 173 ":" 174 ":" 175 ":" 176 ":" 177 ":" 178 ":" 179 ":" 180 ":" 181 ":" 182 ":" 183 ":" 184 ":" 185 ":" 186 ":" 187 ":" 188 ":" 189 ":" 190 ":" 191 ":" 192 ":" 193 ":" 194 ":" 195 ":" 196 ":" 197 ":" 198 ":" 199 ":" 200 ":" 201 ":" 202 ":" 203 ":" 204 ":" 205 ":" 206 ":" 207 ":" 208 ":" 209 ":" 210 ":" 211 ":" 212 ":" 213 ":" 214 ":" 215 ":" 216 ":" 217 ":" 218 ":" 219 ":" 220 ":" 221 ":" 222 ":" 223 ":" 224 ":" 225 ":" 226 ":" 227 ":" 228 ":" 229 ":" 230 ":" 231 ":" 232 ":" 233 ":" 234 ":" 235 ":" 236 ":" 237 ":" 238 ":" 239 ":" 240 ":" 241 ":" 242 ":" 243 ":" 244 ":" 245 ":" 246 ":" 247 ":" 248 ":" 249 ":" 250 ":" 251 ":" 252 ":" 253 ":" 254 ":" 255 ":" ;
VAL_ 456 AEB_DecREQ 0 "0b:No Request" 1 "1b:Request" ;
VAL_ 456 ABA_Level 0 "0:level 0 (no level)" 1 "1:level 1" 2 "2:level 2" 3 "3:level 3" ;
VAL_ 456 ABA_REQ 0 "0b:No Request" 1 "1b:Request" ;
VAL_ 456 AWB_Level 0 "0:no level" 1 "1:level 1" 2 "2:level 2" 3 "3:level 3" 4 "4-7:reserved" 5 "4-7:reserved" 6 "4-7:reserved" ;
VAL_ 456 AWB_REQ 0 "0b:No Request" 1 "1b:Request" ;
VAL_ 456 PREFILL_REQ 0 "0b:No Request" 1 "1b:Request" ;
VAL_ 456 CPFunctionAlive 0 "0b:normal" 1 "1b:failure" ;
VAL_ 456 CPFunctionAct 0 "0b:off退出功能" 1 "1b:active" ;
VAL_ 456 CP_CDDReq 0 "0b:No Request" 1 "1b:Request" ;
VAL_ 456 ALIVE_CNT 0 ":" 1 ":" 2 ":" 3 ":" 4 ":" 5 ":" 6 ":" 7 ":" 8 ":" 9 ":" 10 ":" 11 ":" 12 ":" 13 ":" 14 ":" 15 ":" ;
VAL_ 456 CP_CDDReqVal 0 ":" 1 ":" 2 ":" 3 ":" 4 ":" 5 ":" 6 ":" 7 ":" 8 ":" 9 ":" 10 ":" 11 ":" 12 ":" 13 ":" 14 ":" 15 ":" 16 ":" 17 ":" 18 ":" 19 ":" 20 ":" 21 ":" 22 ":" 23 ":" 24 ":" 25 ":" 26 ":" 27 ":" 28 ":" 29 ":" 30 ":" 31 ":" 32 ":" 33 ":" 34 ":" 35 ":" 36 ":" 37 ":" 38 ":" 39 ":" 40 ":" 41 ":" 42 ":" 43 ":" 44 ":" 45 ":" 46 ":" 47 ":" 48 ":" 49 ":" 50 ":" 51 ":" 52 ":" 53 ":" 54 ":" 55 ":" 56 ":" 57 ":" 58 ":" 59 ":" 60 ":" 61 ":" 62 ":" 63 ":" 64 ":" 65 ":" 66 ":" 67 ":" 68 ":" 69 ":" 70 ":" 71 ":" 72 ":" 73 ":" 74 ":" 75 ":" 76 ":" 77 ":" 78 ":" 79 ":" 80 ":" 81 ":" 82 ":" 83 ":" 84 ":" 85 ":" 86 ":" 87 ":" 88 ":" 89 ":" 90 ":" 91 ":" 92 ":" 93 ":" 94 ":" 95 ":" 96 ":" 97 ":" 98 ":" 99 ":" 100 ":" 101 ":" 102 ":" 103 ":" 104 ":" 105 ":" 106 ":" 107 ":" 108 ":" 109 ":" 110 ":" 111 ":" 112 ":" 113 ":" 114 ":" 115 ":" 116 ":" 117 ":" 118 ":" 119 ":" 120 ":" 121 ":" 122 ":" 123 ":" 124 ":" 125 ":" 126 ":" 127 ":" 128 ":" 129 ":" 130 ":" 131 ":" 132 ":" 133 ":" 134 ":" 135 ":" 136 ":" 137 ":" 138 ":" 139 ":" 140 ":" 141 ":" 142 ":" 143 ":" 144 ":" 145 ":" 146 ":" 147 ":" 148 ":" 149 ":" 150 ":" 151 ":" 152 ":" 153 ":" 154 ":" 155 ":" 156 ":" 157 ":" 158 ":" 159 ":" 160 ":" 161 ":" 162 ":" 163 ":" 164 ":" 165 ":" 166 ":" 167 ":" 168 ":" 169 ":" 170 ":" 171 ":" 172 ":" 173 ":" 174 ":" 175 ":" 176 ":" 177 ":" 178 ":" 179 ":" 180 ":" 181 ":" 182 ":" 183 ":" 184 ":" 185 ":" 186 ":" 187 ":" 188 ":" 189 ":" 190 ":" 191 ":" 192 ":" 193 ":" 194 ":" 195 ":" 196 ":" 197 ":" 198 ":" 199 ":" 200 ":" 201 ":" 202 ":" 203 ":" 204 ":" 205 ":" 206 ":" 207 ":" 208 ":" 209 ":" 210 ":" 211 ":" 212 ":" 213 ":" 214 ":" 215 ":" 216 ":" 217 ":" 218 ":" 219 ":" 220 ":" 221 ":" 222 ":" 223 ":" 224 ":" 225 ":" 226 ":" 227 ":" 228 ":" 229 ":" 230 ":" 231 ":" 232 ":" 233 ":" 234 ":" 235 ":" 236 ":" 237 ":" 238 ":" 239 ":" 240 ":" 241 ":" 242 ":" 243 ":" 244 ":" 245 ":" 246 ":" 247 ":" 248 ":" 249 ":" 250 ":" 251 ":" 252 ":" 253 ":" 254 ":" 255 ":" ;
VAL_ 456 CP_StandstillReq 0 "0b:No Request" 1 "1b:Request" ;
VAL_ 456 EmFunctionActFlag 0 "000b:No function active" 1 "001b:AEB active" 2 "010b:MEB active" 3 "011b:FCTB active" 4 "100b:RCTB active" 5 "101b-111b:Reserved" 6 "101b-111b:Reserved" ;
VAL_ 456 CP_DriveOff 0 "0b:No Request" 1 "1b:Request" ;
VAL_ 456 CHKSUM_DBS 0 ":" 1 ":" 2 ":" 3 ":" 4 ":" 5 ":" 6 ":" 7 ":" 8 ":" 9 ":" 10 ":" 11 ":" 12 ":" 13 ":" 14 ":" 15 ":" 16 ":" 17 ":" 18 ":" 19 ":" 20 ":" 21 ":" 22 ":" 23 ":" 24 ":" 25 ":" 26 ":" 27 ":" 28 ":" 29 ":" 30 ":" 31 ":" 32 ":" 33 ":" 34 ":" 35 ":" 36 ":" 37 ":" 38 ":" 39 ":" 40 ":" 41 ":" 42 ":" 43 ":" 44 ":" 45 ":" 46 ":" 47 ":" 48 ":" 49 ":" 50 ":" 51 ":" 52 ":" 53 ":" 54 ":" 55 ":" 56 ":" 57 ":" 58 ":" 59 ":" 60 ":" 61 ":" 62 ":" 63 ":" 64 ":" 65 ":" 66 ":" 67 ":" 68 ":" 69 ":" 70 ":" 71 ":" 72 ":" 73 ":" 74 ":" 75 ":" 76 ":" 77 ":" 78 ":" 79 ":" 80 ":" 81 ":" 82 ":" 83 ":" 84 ":" 85 ":" 86 ":" 87 ":" 88 ":" 89 ":" 90 ":" 91 ":" 92 ":" 93 ":" 94 ":" 95 ":" 96 ":" 97 ":" 98 ":" 99 ":" 100 ":" 101 ":" 102 ":" 103 ":" 104 ":" 105 ":" 106 ":" 107 ":" 108 ":" 109 ":" 110 ":" 111 ":" 112 ":" 113 ":" 114 ":" 115 ":" 116 ":" 117 ":" 118 ":" 119 ":" 120 ":" 121 ":" 122 ":" 123 ":" 124 ":" 125 ":" 126 ":" 127 ":" 128 ":" 129 ":" 130 ":" 131 ":" 132 ":" 133 ":" 134 ":" 135 ":" 136 ":" 137 ":" 138 ":" 139 ":" 140 ":" 141 ":" 142 ":" 143 ":" 144 ":" 145 ":" 146 ":" 147 ":" 148 ":" 149 ":" 150 ":" 151 ":" 152 ":" 153 ":" 154 ":" 155 ":" 156 ":" 157 ":" 158 ":" 159 ":" 160 ":" 161 ":" 162 ":" 163 ":" 164 ":" 165 ":" 166 ":" 167 ":" 168 ":" 169 ":" 170 ":" 171 ":" 172 ":" 173 ":" 174 ":" 175 ":" 176 ":" 177 ":" 178 ":" 179 ":" 180 ":" 181 ":" 182 ":" 183 ":" 184 ":" 185 ":" 186 ":" 187 ":" 188 ":" 189 ":" 190 ":" 191 ":" 192 ":" 193 ":" 194 ":" 195 ":" 196 ":" 197 ":" 198 ":" 199 ":" 200 ":" 201 ":" 202 ":" 203 ":" 204 ":" 205 ":" 206 ":" 207 ":" 208 ":" 209 ":" 210 ":" 211 ":" 212 ":" 213 ":" 214 ":" 215 ":" 216 ":" 217 ":" 218 ":" 219 ":" 220 ":" 221 ":" 222 ":" 223 ":" 224 ":" 225 ":" 226 ":" 227 ":" 228 ":" 229 ":" 230 ":" 231 ":" 232 ":" 233 ":" 234 ":" 235 ":" 236 ":" 237 ":" 238 ":" 239 ":" 240 ":" 241 ":" 242 ":" 243 ":" 244 ":" 245 ":" 246 ":" 247 ":" 248 ":" 249 ":" 250 ":" 251 ":" 252 ":" 253 ":" 254 ":" 255 ":" ;
VAL_ 691 ADCU_DriAngleRequestCtrl 0 "0:No request" 1 "1:Request" ;
VAL_ 691 ADCU_DriAngleRequest_Vld 0 "0:Valid" 1 "1:Invalid" ;
VAL_ 691 ADCU_ControlMode 0 "0b:No request" 1 "01b:LKA active" 2 "10b:APA active" 3 "11b:Reserved" ;
VAL_ 691 ADCU_HapcWarnReq 0 "0:Normal" 1 "1:Warning" 2 "2:Reserved" ;
VAL_ 691 ADCU_ESS_Mode 0 "00b:Reserve" 1 "01b:ESS active" 2 "10b:No request" 3 "11b:Reserve" ;
VAL_ 691 ADCU_DriAngleRequest 0 ":" 1 ":" 2 ":" 3 ":" 4 ":" 5 ":" 6 ":" 7 ":" 8 ":" 9 ":" 10 ":" 11 ":" 12 ":" 13 ":" 14 ":" 15 ":" 16 ":" 17 ":" 18 ":" 19 ":" 20 ":" 21 ":" 22 ":" 23 ":" 24 ":" 25 ":" 26 ":" 27 ":" 28 ":" 29 ":" 30 ":" 31 ":" 32 ":" 33 ":" 34 ":" 35 ":" 36 ":" 37 ":" 38 ":" 39 ":" 40 ":" 41 ":" 42 ":" 43 ":" 44 ":" 45 ":" 46 ":" 47 ":" 48 ":" 49 ":" 50 ":" 51 ":" 52 ":" 53 ":" 54 ":" 55 ":" 56 ":" 57 ":" 58 ":" 59 ":" 60 ":" 61 ":" 62 ":" 63 ":" 64 ":" 65 ":" 66 ":" 67 ":" 68 ":" 69 ":" 70 ":" 71 ":" 72 ":" 73 ":" 74 ":" 75 ":" 76 ":" 77 ":" 78 ":" 79 ":" 80 ":" 81 ":" 82 ":" 83 ":" 84 ":" 85 ":" 86 ":" 87 ":" 88 ":" 89 ":" 90 ":" 91 ":" 92 ":" 93 ":" 94 ":" 95 ":" 96 ":" 97 ":" 98 ":" 99 ":" 100 ":" 101 ":" 102 ":" 103 ":" 104 ":" 105 ":" 106 ":" 107 ":" 108 ":" 109 ":" 110 ":" 111 ":" 112 ":" 113 ":" 114 ":" 115 ":" 116 ":" 117 ":" 118 ":" 119 ":" 120 ":" 121 ":" 122 ":" 123 ":" 124 ":" 125 ":" 126 ":" 127 ":" 128 ":" 129 ":" 130 ":" 131 ":" 132 ":" 133 ":" 134 ":" 135 ":" 136 ":" 137 ":" 138 ":" 139 ":" 140 ":" 141 ":" 142 ":" 143 ":" 144 ":" 145 ":" 146 ":" 147 ":" 148 ":" 149 ":" 150 ":" 151 ":" 152 ":" 153 ":" 154 ":" 155 ":" 156 ":" 157 ":" 158 ":" 159 ":" 160 ":" 161 ":" 162 ":" 163 ":" 164 ":" 165 ":" 166 ":" 167 ":" 168 ":" 169 ":" 170 ":" 171 ":" 172 ":" 173 ":" 174 ":" 175 ":" 176 ":" 177 ":" 178 ":" 179 ":" 180 ":" 181 ":" 182 ":" 183 ":" 184 ":" 185 ":" 186 ":" 187 ":" 188 ":" 189 ":" 190 ":" 191 ":" 192 ":" 193 ":" 194 ":" 195 ":" 196 ":" 197 ":" 198 ":" 199 ":" 200 ":" 201 ":" 202 ":" 203 ":" 204 ":" 205 ":" 206 ":" 207 ":" 208 ":" 209 ":" 210 ":" 211 ":" 212 ":" 213 ":" 214 ":" 215 ":" 216 ":" 217 ":" 218 ":" 219 ":" 220 ":" 221 ":" 222 ":" 223 ":" 224 ":" 225 ":" 226 ":" 227 ":" 228 ":" 229 ":" 230 ":" 231 ":" 232 ":" 233 ":" 234 ":" 235 ":" 236 ":" 237 ":" 238 ":" 239 ":" 240 ":" 241 ":" 242 ":" 243 ":" 244 ":" 245 ":" 246 ":" 247 ":" 248 ":" 249 ":" 250 ":" 251 ":" 252 ":" 253 ":" 254 ":" 255 ":" ;
